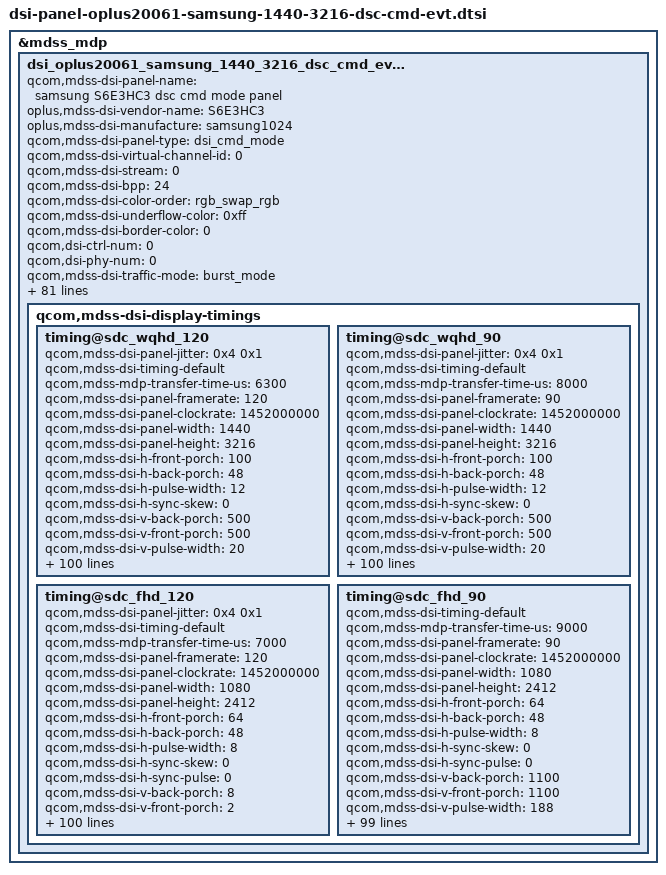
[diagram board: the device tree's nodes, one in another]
&mdss_mdp {
	dsi_oplus20061_samsung_1440_3216_dsc_cmd_evt: qcom,mdss_dsi_oplus20061_samsung_1440_3216_dsc_cmd_evt {
		qcom,mdss-dsi-panel-name = "samsung S6E3HC3 dsc cmd mode panel";
		oplus,mdss-dsi-vendor-name = "S6E3HC3";
		oplus,mdss-dsi-manufacture = "samsung1024";
		qcom,mdss-dsi-panel-type = "dsi_cmd_mode";
		qcom,mdss-dsi-virtual-channel-id = <0>;
		qcom,mdss-dsi-stream = <0>;
		qcom,mdss-dsi-bpp = <24>;
		qcom,mdss-dsi-color-order = "rgb_swap_rgb";
		qcom,mdss-dsi-underflow-color = <0xff>;
		qcom,mdss-dsi-border-color = <0>;
		qcom,dsi-ctrl-num = <0>;
		qcom,dsi-phy-num = <0>;
		qcom,mdss-dsi-traffic-mode = "burst_mode";
		qcom,mdss-dsi-lane-map = "lane_map_0123";
		qcom,mdss-dsi-bllp-eof-power-mode;
		qcom,mdss-dsi-bllp-power-mode;
		qcom,mdss-dsi-lane-0-state;
		qcom,mdss-dsi-lane-1-state;
		qcom,mdss-dsi-lane-2-state;
		qcom,mdss-dsi-lane-3-state;
		qcom,mdss-dsi-dma-trigger = "trigger_sw";
		qcom,mdss-loading-effect;
		qcom,mdss-dsi-mdp-trigger = "none";
		qcom,mdss-dsi-reset-sequence = <1 10>, <0 5>, <1 10>;
		qcom,mdss-dsi-te-pin-select = <1>;
		qcom,mdss-dsi-te-dcs-command = <1>;
		qcom,mdss-pan-physical-width-dimension = <71>;
		qcom,mdss-pan-physical-height-dimension = <157>;
		qcom,mdss-dsi-init-delay-us = <1000>;
		qcom,mdss-dsi-te-check-enable;
		qcom,mdss-dsi-te-using-te-pin;
		qcom,mdss-dsi-lp11-init;
		qcom,mdss-dsi-wr-mem-start = <0x2c>;
		qcom,mdss-dsi-wr-mem-continue = <0x3c>;
		/* HDR Setting */
		qcom,mdss-dsi-panel-hdr-enabled;
		qcom,mdss-dsi-panel-hdr-color-primaries = <15635 16450 34000 16000 13250 34500 7500 3000>;
		qcom,mdss-dsi-panel-peak-brightness = <5400000>;
		qcom,mdss-dsi-panel-average-brightness = <2000000>;
		qcom,mdss-dsi-panel-blackness-level = <4000>;

		qcom,esd-check-enabled;
		qcom,mdss-dsi-panel-status-check-mode = "reg_read";
		qcom,mdss-dsi-panel-status-command = [
						06 01 00 01 05 00 02 E9 00
						06 01 00 01 05 00 02 EE 00
						06 01 00 01 05 00 02 0A 00
						];
		qcom,mdss-dsi-panel-status-command-state = "dsi_hs_mode";
		qcom,mdss-dsi-panel-status-value = <0x00 0x00 0x00 0x00 0x00 0x9F>;
		qcom,mdss-dsi-panel-status-read-length = <4 1 1>;

		qcom,dynamic-mode-switch-enabled;
		qcom,dynamic-mode-switch-type = "dynamic-resolution-switch-immediate";
		qcom,mdss-dsi-display-timings {
			timing@sdc_wqhd_120{
				qcom,mdss-dsi-panel-jitter = <0x4 0x1>;
				qcom,mdss-dsi-timing-default;
				qcom,mdss-mdp-transfer-time-us = <6300>;
				qcom,mdss-dsi-panel-framerate = <120>;
				qcom,mdss-dsi-panel-clockrate = <1452000000>;
				qcom,mdss-dsi-panel-width = <1440>;
				qcom,mdss-dsi-panel-height = <3216>;

				qcom,mdss-dsi-h-front-porch = <100>;
				qcom,mdss-dsi-h-back-porch = <48>;
				qcom,mdss-dsi-h-pulse-width = <12>;
				qcom,mdss-dsi-h-sync-skew = <0>;
				qcom,mdss-dsi-v-back-porch = <500>;
				qcom,mdss-dsi-v-front-porch = <500>;
				qcom,mdss-dsi-v-pulse-width = <20>;
				qcom,mdss-dsi-h-sync-pulse = <0>;

				qcom,mdss-dsi-h-left-border = <0>;
				qcom,mdss-dsi-h-right-border = <0>;
				qcom,mdss-dsi-v-top-border = <0>;
				qcom,mdss-dsi-v-bottom-border = <0>;

				qcom,dsi-select-clocks = "mux_byte_clk0", "mux_pixel_clk0";

				oplus,fod-on-vblank = <2>;
				oplus,fod-off-vblank = <3>;
				qcom,mdss-dsi-panel-read-register-open-command = [
					39 01 00 00 00 00 03 F0 5A 5A
					];
				qcom,mdss-dsi-panel-id1-command = [
					06 01 00 00 00 00 01 E9
					];
				qcom,mdss-dsi-panel-read-register-close-command = [
					39 01 00 00 00 00 03 F0 A5 A5
					];
				qcom,mdss-dsi-timing-switch-command = [
					/* Resolution setting */
					/* CASET/PASET Setting */
					39 01 00 00 00 00 05 2A 00 00 05 9F
					39 01 00 00 00 00 05 2B 00 00 0C 8F
					/* Scaler Setting */
					39 01 00 00 00 00 03 F0 5A 5A
					15 01 00 00 00 00 02 C3 0C
					39 01 00 00 00 00 03 F0 A5 A5

					/* OPLUS ADFR OFF */
					39 00 00 00 00 00 03 F0 5A 5A				/* Level2 key Access Enable */
					39 00 00 00 00 00 03 FC 5A 5A				/* Level3 key Access Enable */
					39 00 00 00 00 00 02 B9 00					/* TP shift fixed*/
					39 00 00 00 00 00 04 B0 00 02 60
					15 00 00 00 00 00 02 60 00					/* OPLUS ADFR off */
					39 00 00 00 00 00 03 F2 00 01				/* 0x01, 0x00 : ADFR ON setting, 0x00, 0x01 : ADFR OFF Setting */
					15 00 00 00 00 00 02 F7 0F
					39 00 00 00 00 00 03 FC A5 A5				/* Level3 key Access Disable */
					39 01 00 00 00 00 03 F0 A5 A5				/* Level2 key Access Disable */

					/* SDC ADFR */
					39 00 00 00 00 00 03 F0 5A 5A				/* Level2 key Access Enable */
					39 00 00 00 00 00 04 B0 00 22 B9			/* TSP_HSYNC Fixed TE*/
					15 00 00 00 00 00 02 B9 21
					39 00 00 00 00 00 04 B0 00 3A B9
					39 00 00 00 00 00 02 B9 02					/* TSP_HSYNC Fixed TE 02:120  03:90 05:60 */
					39 00 00 00 00 00 04 B0 00 16 F2
					39 00 00 00 00 00 03 F2 1B 50				/* 0x1B, 0x50 : 120hz,  0x24, 0x70 : 90hz */
					39 00 00 00 00 00 03 BD 21 02				/* 0x21, 0x02 : 120hz,  0x21, 0x03 : 90hz */
					15 00 00 00 00 00 02 60 00					/* 0x00 : 120hz,  0x08 : 90hz */
					15 00 00 00 00 00 02 F7 0F
					39 01 00 00 11 00 03 F0 A5 A5				/* Level2 key Access Disable, wait 17ms for TE stable*/

					39 00 00 00 00 00 03 F0 5A 5A				/* Level2 key Access Enable */
					15 00 00 00 00 00 02 BD 23					/* 21 : Manual On  23 Auto On */
					39 00 00 00 00 00 04 B0 00 14 BD
					15 00 00 00 00 00 02 BD 0B					/* SDC auto mode min fps setting 0B: 10hz */
					15 00 00 00 00 00 02 F7 0F
					39 01 00 00 00 00 03 F0 A5 A5				/* Level2 key Access Disable */
				];
				qcom,mdss-dsi-on-command = [
					/* PPS setting */
					39 01 00 00 0B 00 5A 9E
					11 00 00 89 30 80 0C 90
					05 A0 00 43 02 D0 02 D0
					02 00 02 C2 00 20 06 89
					00 0A 00 0F 01 D2 01 24
					18 00 10 F0 03 0C 20 00
					06 0B 0B 33 0E 1C 2A 38
					46 54 62 69 70 77 79 7B
					7D 7E 01 02 01 00 09 40
					09 BE 19 FC 19 FA 19 F8
					1A 38 1A 78 1A B6 2A B6
					2A F4 2A F4 4B 34 63 74 00
					/* DSC enable */
					15 01 00 00 00 00 02 9D 01
					/*Sleep out */
					05 01 00 00 07 00 01 11

					/* TSP_VSYNC Fixed 120Hz Setting */
					39 01 00 00 00 00 03 F0 5A 5A
					39 01 00 00 00 00 04 B0 00 22 B9
					15 01 00 00 00 00 02 B9 21
					39 01 00 00 00 00 04 B0 00 3A B9
					15 01 00 00 00 00 02 B9 02
					15 01 00 00 00 00 02 F7 0F
					39 01 00 00 78 00 03 F0 A5 A5

					/* SDC ADFR 120hz */
					39 01 00 00 00 00 03 F0 5A 5A				/* Level2 key Access Enable */
					39 01 00 00 00 00 04 B0 00 16 F2
					39 01 00 00 00 00 03 F2 1B 50				/* 0x1B, 0x50 : 120hz,  0x24, 0x70 : 90hz */
					39 01 00 00 00 00 03 BD 21 02				/* 0x21, 0x02 : 120hz,  0x21, 0x03 : 90hz */
					15 01 00 00 00 00 02 60 00					/* 0x00 : 120hz,  0x08 : 90hz */
					15 01 00 00 00 00 02 F7 0F
					39 01 00 00 00 00 03 F0 A5 A5				/* Level2 key Access Disable */

					/* SDC auto mode */
					39 01 00 00 00 00 03 F0 5A 5A				/* Level2 key Access Enable */
					15 01 00 00 00 00 02 BD 23					/* 21 : Manual On  23 Auto On */
					39 00 00 00 00 00 04 B0 00 14 BD
					15 00 00 00 00 00 02 BD 0B					/* SDC auto mode min fps setting 0B: 10hz */
					15 01 00 00 00 00 02 F7 0F
					39 01 00 00 00 00 03 F0 A5 A5				/* Level2 key Access Disable */

					/* Common Setting */
					/* FQ_CON Setting */
					39 01 00 00 00 00 03 F0 5A 5A				/* Level2 key Access Enable */
					39 01 00 00 00 00 03 F2 00 01				/* FQ_CON Setting */
					39 01 00 00 00 00 03 F0 A5 A5				/* Level2 key Access Disable */
					/* TE(Vsync) ON/OFF */
					15 01 00 00 00 00 02 35 00					/* TE On(Vsync) */

					/* Resolution setting */
					/* CASET/PASET Setting */
					39 01 00 00 00 00 05 2A 00 00 05 9F
					39 01 00 00 00 00 05 2B 00 00 0C 8F
					/* Scaler Setting */
					39 01 00 00 00 00 03 F0 5A 5A
					15 01 00 00 00 00 02 C3 0C
					39 01 00 00 00 00 03 F0 A5 A5

					/* Loading effect compensation Control */
					39 01 00 00 00 00 03 F0 5A 5A				/* TEST KEY Enable */
					39 01 00 00 00 00 04 B0 02 B6 1D				/* Global Para */
					15 01 00 00 00 00 02 1D 25					/* Loading effect compensation Setting, 0x25: mode ON, 0x05:mode ON */
					39 01 00 00 00 00 03 F0 A5 A5

					/* Brightness Control */
					/* Dimming Setting */
					39 01 00 00 00 00 03 F0 5A 5A				/* Level2 key Access Enable */
					39 01 00 00 00 00 04 B0 00 0D 63
					15 01 00 00 00 00 02 63 01					/* Dimming Speed Setting */
					39 01 00 00 00 00 04 B0 00 0C 63
					15 01 00 00 00 00 02 63 20					/* ELVSS Dim Setting */
					39 01 00 00 00 00 03 F0 A5 A5				/* Level2 key Access Disable */
					15 01 00 00 00 00 02 53 28					/* WRCTRLD */
					39 01 00 00 00 00 03 51 07 FF				/* WRDISBV */
					15 01 00 00 00 00 02 F7 0F

					/** OPEC ON ***/
					39 01 00 00 00 00 03 F0 5A 5A
					39 01 00 00 00 00 04 B0 00 52 1F
					39 01 00 00 00 00 02 1F 02
					39 01 00 00 00 00 04 B0 00 54 1F
					39 01 00 00 00 00 02 1F 01
					39 01 00 00 00 00 03 F0 A5 A5

					/* ACL Mode */
					39 01 00 00 00 00 03 F0 5A 5A				/* Level2 key Access Enable */
					15 01 00 00 00 00 02 55 00					/* WRCABC, 0x00 : ACL Off */
					39 01 00 00 00 00 03 F0 A5 A5				/* Level2 key Access Disable */

					/* ELVSS DIM OFF  */
					39 01 00 00 00 00 03 F0 5A 5A
					39 01 00 00 00 00 04 B0 00 0C 63
					15 01 00 00 00 00 02 63 00
					39 01 00 00 00 00 03 F0 A5 A5

					//05 01 00 00 00 00 01 29
				];
				qcom,mdss-dsi-post-on-backlight = [
					/* Display On */
					05 01 00 00 00 00 01 29
				];
				qcom,mdss-dsi-off-command=[
					05 01 00 00 0A 00 02 28 00
					05 01 00 00 78 00 02 10 00
				];
				qcom,mdss-dsi-lp1-command = [
					//05 01 00 00 11 00 01 28
					/* AOD Mode ON Setting */
					39 01 00 00 00 00 03 F0 5A 5A
					15 01 00 00 00 00 02 53 24
					15 01 00 00 00 00 02 6A 00
					15 01 00 00 00 00 02 F7 0F
					15 01 00 00 00 00 02 49 01
					39 01 00 00 24 00 03 F0 A5 A5
					05 01 00 00 00 00 01 29
				];
				qcom,mdss-dsi-nolp-command = [
					/* AOD OFF */
					39 01 00 00 00 00 03 F0 5A 5A
					15 01 00 00 00 00 02 53 20
					15 01 00 00 00 00 02 F7 0F
					15 01 00 00 00 00 02 49 02
					39 01 00 00 00 00 03 F0 A5 A5
					/* ELVSS DIM OFF  */
					39 01 00 00 00 00 03 F0 5A 5A
					39 01 00 00 00 00 04 B0 00 0C 63
					15 01 00 00 00 00 02 63 00
					39 01 00 00 00 00 03 F0 A5 A5
					/* SDC ADFR */
					39 00 00 00 00 00 03 F0 5A 5A				/* Level2 key Access Enable */
					39 00 00 00 00 00 04 B0 00 22 B9			/* TSP_HSYNC Fixed TE*/
					15 00 00 00 00 00 02 B9 21
					39 00 00 00 00 00 04 B0 00 3A B9
					39 00 00 00 00 00 02 B9 02					/* TSP_HSYNC Fixed TE 02:120  03:90 05:60 */
					39 00 00 00 00 00 04 B0 00 16 F2
					39 00 00 00 00 00 03 F2 1B 50				/* 0x1B, 0x50 : 120hz,  0x24, 0x70 : 90hz */
					39 00 00 00 00 00 03 BD 21 02				/* 0x21, 0x02 : 120hz,  0x21, 0x03 : 90hz */
					15 00 00 00 00 00 02 60 00					/* 0x00 : 120hz,  0x08 : 90hz */
					15 00 00 00 00 00 02 F7 0F
					39 01 00 00 11 00 03 F0 A5 A5				/* Level2 key Access Disable, wait 17ms for TE stable*/

					/* Normal Mode */
					39 01 00 00 00 00 03 F0 5A 5A
					39 01 00 00 00 00 04 B0 00 01 49
					15 01 00 00 00 00 02 49 01
					15 01 00 00 00 00 02 53 20
					15 01 00 00 00 00 02 F7 0F
					39 01 00 00 00 00 03 F0 A5 A5
					/* AOR 16% */
					//39 01 00 00 00 00 03 F0 5A 5A
					//39 01 00 00 00 00 04 B0 00 01 BD
					//39 01 00 00 00 00 02 BD 02
					//39 01 00 00 00 00 04 B0 02 B9 65
					//39 01 00 00 00 00 07 65 01 5E 01 5E 01 5E
					//39 01 00 00 00 00 02 F7 0F
					//39 01 00 00 00 00 03 F0 A5 A5
				];
				qcom,mdss-dsi-aod-hbm-on-command = [
					/* Loading OFF */
					39 01 00 00 00 00 03 F0 5A 5A
					39 01 00 00 00 00 04 B0 02 B6 1D
					39 01 00 00 00 00 02 1D 05
					39 01 00 00 00 00 03 F0 A5 A5
					/* AOD OFF */
					39 01 00 00 00 00 03 F0 5A 5A
					39 01 00 00 00 00 02 53 20
					15 01 00 00 00 00 02 F7 0F
					15 01 00 00 00 00 02 49 02
					39 01 00 00 00 00 03 F0 A5 A5
					/* AOR 1.6% */
					39 01 00 00 00 00 03 F0 5A 5A
					39 01 00 00 00 00 04 B0 00 01 BD
					39 01 00 00 00 00 02 BD 00
					39 01 00 00 00 00 04 B0 02 B9 65
					39 01 00 00 00 00 07 65 00 AC 00 AC 00 AC
					39 01 00 00 00 00 02 F7 0F
					39 01 00 00 00 00 03 F0 A5 A5
					/* Hbm ON */
					39 01 00 00 00 00 03 F0 5A 5A
					39 01 00 00 00 00 04 B0 00 01 49
					39 01 00 00 00 00 02 49 00
					15 01 00 00 00 00 02 53 E0
					39 01 00 00 00 00 03 51 0B 7F
					15 01 00 00 00 00 02 F7 0F
					39 01 00 00 00 00 03 F0 A5 A5
				];
				qcom,mdss-dsi-aod-hbm-off-command = [
					/* HBM OFF */
					39 01 00 00 00 00 03 F0 5A 5A
					39 01 00 00 00 00 04 B0 00 01 49
					15 01 00 00 00 00 02 49 01
					15 01 00 00 00 00 02 53 20
					15 01 00 00 00 00 02 F7 0F
					39 01 00 00 00 00 03 F0 A5 A5
					/* AOD ON */
					39 01 00 00 00 00 03 F0 5A 5A
					15 01 00 00 00 00 02 53 24
					15 01 00 00 00 00 02 6A 00
					15 01 00 00 00 00 02 F7 0F
					39 01 00 00 00 00 02 49 01
					39 01 00 00 00 00 03 F0 A5 A5
				];
				qcom,mdss-dsi-hbm-off-command = [
					39 01 00 00 00 00 03 F0 5A 5A
					39 01 00 00 00 00 04 B0 00 01 49
					39 01 00 00 00 00 02 49 01
					15 01 00 00 00 00 02 53 20
					//39 01 00 00 05 00 03 51 05 14
					15 01 00 00 00 00 02 F7 0F
					39 01 00 00 00 00 03 F0 A5 A5
					/* Loading ON */
					//39 01 00 00 00 00 03 F0 5A 5A
					//39 01 00 00 00 00 04 B0 02 B6 1D
					//39 01 00 00 00 00 02 1D 25
					//39 01 00 00 00 00 03 F0 A5 A5
				];
				qcom,mdss-dsi-hbm-on-command = [
					/* Loading OFF */
					39 01 00 00 00 00 03 F0 5A 5A
					39 01 00 00 00 00 04 B0 02 B6 1D
					39 01 00 00 00 00 02 1D 05
					39 01 00 00 00 00 03 F0 A5 A5
					/* AOR 1.6% */
					39 01 00 00 00 00 03 F0 5A 5A
					39 01 00 00 00 00 04 B0 00 01 BD
					39 01 00 00 00 00 02 BD 00
					39 01 00 00 00 00 04 B0 02 B9 65
					39 01 00 00 00 00 07 65 00 AC 00 AC 00 AC
					39 01 00 00 00 00 02 F7 0F
					39 01 00 00 00 00 03 F0 A5 A5
					/* Hbm ON */
					39 01 00 00 00 00 03 F0 5A 5A
					39 01 00 00 00 00 04 B0 00 01 49
					39 01 00 00 00 00 02 49 00
					15 01 00 00 00 00 02 53 E0
					39 01 00 00 00 00 03 51 0B 7F
					15 01 00 00 00 00 02 F7 0F
					39 01 00 00 00 00 03 F0 A5 A5
				];
				qcom,mdss-dsi-normal-hbm-on-command = [
					/* Loading OFF */
					39 01 00 00 00 00 03 F0 5A 5A
					39 01 00 00 00 00 04 B0 02 B6 1D
					39 01 00 00 00 00 02 1D 05
					39 01 00 00 00 00 03 F0 A5 A5
					/* AOR 1.6% */
					39 01 00 00 00 00 03 F0 5A 5A
					39 01 00 00 00 00 04 B0 00 01 BD
					39 01 00 00 00 00 02 BD 00
					39 01 00 00 00 00 04 B0 02 B9 65
					39 01 00 00 00 00 07 65 00 AC 00 AC 00 AC
					39 01 00 00 00 00 02 F7 0F
					39 01 00 00 00 00 03 F0 A5 A5
					/* Hbm ON */
					39 01 00 00 00 00 03 F0 5A 5A
					39 01 00 00 00 00 04 B0 00 01 49
					39 01 00 00 00 00 02 49 00
					15 01 00 00 00 00 02 53 E0
					39 01 00 00 00 00 03 51 0B 7F
					15 01 00 00 00 00 02 F7 0F
					39 01 00 00 00 00 03 F0 A5 A5
				];
				qcom,mdss-dsi-aod-high-mode-command = [
					/* AOD 50nit */
					39 01 00 00 00 00 03 F0 5A 5A
					15 01 00 00 00 00 02 53 24
					39 01 00 00 00 00 02 6A 00
					39 01 00 00 00 00 03 F0 A5 A5
				];
				qcom,mdss-dsi-aod-low-mode-command = [
					/* AOD 10nit */
					39 01 00 00 00 00 03 F0 5A 5A
					15 01 00 00 00 00 02 53 27
					39 01 00 00 00 00 02 6A 00
					39 01 00 00 00 00 03 F0 A5 A5
				];
				qcom,mdss-dsi-seed-off-command = [
					/* SEED CRC OFF*/
					15 01 00 00 00 00 02 1C 00
					/* SEED CRC BYPASS */
					39 01 00 00 00 00 03 F0 5A 5A
					15 01 00 00 00 00 02 1D 01
					39 01 00 00 00 00 03 F0 A5 A5
				];
				qcom,mdss-dsi-seed-0-command = [
					/* SEED CRC Setting*/
					15 01 00 00 00 00 02 1C 05
					39 01 00 00 00 00 03 F0 5A 5A
					39 01 00 00 00 00 04 B0 00 01 1D
					/* SEED DCI-P3 Setting*/
					39 01 00 00 00 00 16 1D FF 00 00 00 FF 00 00 00 FF 00 FF FF FF 00 FF FF FF 00 FF FF FF
					15 01 00 00 00 00 02 1D 00
					39 01 00 00 00 00 03 F0 A5 A5
				];
				qcom,mdss-dsi-seed-1-command = [
					/* SEED CRC Setting*/
					15 01 00 00 00 00 02 1C 05
					39 01 00 00 00 00 03 F0 5A 5A
					39 01 00 00 00 00 04 B0 00 01 1D
					/* SEED DCI-P3 Setting*/
					39 01 00 00 00 00 16 1D FF 00 00 00 FF 00 00 00 FF 00 FF FF FF 00 FF FF FF 00 FF FF FF
					15 01 00 00 00 00 02 1D 00
					39 01 00 00 00 00 03 F0 A5 A5
				];
				qcom,mdss-dsi-seed-2-command = [
					/* SEED CRC Setting*/
					15 01 00 00 00 00 02 1C 05
					39 01 00 00 00 00 03 F0 5A 5A
					39 01 00 00 00 00 04 B0 00 01 1D
					/* SEED DCI-P3 Setting*/
					39 01 00 00 00 00 16 1D FF 00 00 00 FF 00 00 00 FF 00 FF FF FF 00 FF FF FF 00 FF FF FF
					15 01 00 00 00 00 02 1D 00
					39 01 00 00 00 00 03 F0 A5 A5
				];
				qcom,mdss-dsi-loading-effect-1-command = [
					39 01 00 00 00 00 03 F0 5A 5A
					39 01 00 00 00 00 04 B0 02 B6 1D
					39 01 00 00 00 00 02 1D 25
					39 01 00 00 00 00 04 B0 01 A5 1F
					39 01 00 00 00 00 09 1F E2 02 02 02 92 2C 6A 80
					39 01 00 00 00 00 04 B0 01 AD 1F
					39 01 00 00 00 00 07 1F 00 00 00 00 FF 90
					39 01 00 00 00 00 04 B0 01 B5 1F
					39 01 00 00 00 00 04 1F 49 00 10
					39 01 00 00 00 00 04 B0 01 BA 1F
					39 01 00 00 00 00 06 1F 05 FF 10 00 00
					39 01 00 00 00 00 04 B0 01 C1 1F
					39 01 00 00 00 00 03 1F 00 00
					39 01 00 00 00 00 04 B0 01 C5 1F
					39 01 00 00 00 00 05 1F 03 FF 21 3C
					39 01 00 00 00 00 03 F0 A5 A5
				];
				qcom,mdss-dsi-loading-effect-2-command = [
					39 01 00 00 00 00 03 F0 5A 5A
					39 01 00 00 00 00 04 B0 02 B6 1D
					39 01 00 00 00 00 02 1D 25
					39 01 00 00 00 00 04 B0 01 A5 1F
					39 01 00 00 00 00 09 1F E2 02 02 02 92 2C 6A 80
					39 01 00 00 00 00 04 B0 01 AD 1F
					39 01 00 00 00 00 07 1F 81 67 8F 72 FF 90
					39 01 00 00 00 00 04 B0 01 B5 1F
					39 01 00 00 00 00 04 1F 49 00 10
					39 01 00 00 00 00 04 B0 01 BA 1F
					39 01 00 00 00 00 06 1F 05 FF 10 00 00
					39 01 00 00 00 00 04 B0 01 C1 1F
					39 01 00 00 00 00 03 1F 00 00
					39 01 00 00 00 00 04 B0 01 C5 1F
					39 01 00 00 00 00 05 1F 03 FF 21 3C
					39 01 00 00 00 00 03 F0 A5 A5
				];
				qcom,mdss-dsi-loading-effect-off-command = [
					39 01 00 00 00 00 03 F0 5A 5A
					39 01 00 00 00 00 04 B0 02 B6 1D
					39 01 00 00 00 00 02 1D 05
					39 01 00 00 00 00 04 B0 01 A5 1F
					39 01 00 00 00 00 09 1F E2 02 02 02 92 2C 6A 80
					39 01 00 00 00 00 04 B0 01 AD 1F
					39 01 00 00 00 00 07 1F 71 27 4E 0B FF 9F
					39 01 00 00 00 00 04 B0 01 B5 1F
					39 01 00 00 00 00 04 1F 49 00 10
					39 01 00 00 00 00 04 B0 01 BA 1F
					39 01 00 00 00 00 06 1F 05 FF 10 00 00
					39 01 00 00 00 00 04 B0 01 C1 1F
					39 01 00 00 00 00 03 1F 00 00
					39 01 00 00 00 00 04 B0 01 C5 1F
					39 01 00 00 00 00 05 1F 03 FF 21 3C
					39 01 00 00 00 00 03 F0 A5 A5
				];
				qcom,mdss-dsi-aod-hbm-on-command-state = "dsi_hs_mode";
				qcom,mdss-dsi-aod-hbm-off-command-state = "dsi_hs_mode";
				qcom,mdss-dsi-timing-switch-command-state = "dsi_hs_mode";
				qcom,mdss-dsi-on-command-state = "dsi_lp_mode";
				qcom,mdss-dsi-off-command-state = "dsi_hs_mode";
				qcom,mdss-dsi-seed-off-command-state = "dsi_hs_mode";
				qcom,mdss-dsi-seed-0-command-state = "dsi_hs_mode";
				qcom,mdss-dsi-seed-1-command-state = "dsi_hs_mode";
				qcom,mdss-dsi-seed-2-command-state = "dsi_hs_mode";
				qcom,mdss-dsi-loading-effect-1-command-state = "dsi_hs_mode";
				qcom,mdss-dsi-loading-effect-2-command-state = "dsi_hs_mode";
				qcom,mdss-dsi-loading-effect-off-command-state = "dsi_hs_mode";
				qcom,mdss-dsi-hbm-on-command-state = "dsi_hs_mode";
				qcom,mdss-dsi-hbm-off-command-state = "dsi_hs_mode";

				qcom,compression-mode = "dsc";
				qcom,lm-split = <720 720>;
				qcom,mdss-dsc-encoders = <2>;
				qcom,mdss-dsc-slice-height = <67>;
				qcom,mdss-dsc-slice-width = <720>;
				qcom,mdss-dsc-slice-per-pkt = <2>;
				qcom,mdss-dsc-bit-per-component = <8>;
				qcom,mdss-dsc-bit-per-pixel = <8>;
				qcom,mdss-dsc-block-prediction-enable;
				qcom,mdss-dsi-panel-id1-command-state = "dsi_lp_mode";
				qcom,mdss-dsi-panel-read-register-open-state = "dsi_lp_mode";
				qcom,mdss-dsi-panel-read-register-close-state = "dsi_lp_mode";
			};
			timing@sdc_wqhd_90{
				qcom,mdss-dsi-panel-jitter = <0x4 0x1>;
				qcom,mdss-dsi-timing-default;
				qcom,mdss-mdp-transfer-time-us = <8000>;
				qcom,mdss-dsi-panel-framerate = <90>;
				qcom,mdss-dsi-panel-clockrate = <1452000000>;
				qcom,mdss-dsi-panel-width = <1440>;
				qcom,mdss-dsi-panel-height = <3216>;

				qcom,mdss-dsi-h-front-porch = <100>;
				qcom,mdss-dsi-h-back-porch = <48>;
				qcom,mdss-dsi-h-pulse-width = <12>;
				qcom,mdss-dsi-h-sync-skew = <0>;
				qcom,mdss-dsi-v-back-porch = <500>;
				qcom,mdss-dsi-v-front-porch = <500>;
				qcom,mdss-dsi-v-pulse-width = <20>;
				qcom,mdss-dsi-h-sync-pulse = <0>;

				qcom,mdss-dsi-h-left-border = <0>;
				qcom,mdss-dsi-h-right-border = <0>;
				qcom,mdss-dsi-v-top-border = <0>;
				qcom,mdss-dsi-v-bottom-border = <0>;

				qcom,dsi-select-clocks = "mux_byte_clk0", "mux_pixel_clk0";

				oplus,fod-on-vblank = <2>;
				oplus,fod-off-vblank = <3>;
				qcom,mdss-dsi-panel-read-register-open-command = [
					39 01 00 00 00 00 03 F0 5A 5A
					];
				qcom,mdss-dsi-panel-id1-command = [
					06 01 00 00 00 00 01 E9
					];
				qcom,mdss-dsi-panel-read-register-close-command = [
					39 01 00 00 00 00 03 F0 A5 A5
					];
				qcom,mdss-dsi-timing-switch-command = [
					/* Resolution setting */
					/* CASET/PASET Setting */
					39 01 00 00 00 00 05 2A 00 00 05 9F
					39 01 00 00 00 00 05 2B 00 00 0C 8F
					/* Scaler Setting */
					39 01 00 00 00 00 03 F0 5A 5A
					15 01 00 00 00 00 02 C3 0C
					39 01 00 00 00 00 03 F0 A5 A5

					/* OPLUS ADFR OFF */
					39 00 00 00 00 00 03 F0 5A 5A				/* Level2 key Access Enable */
					39 00 00 00 00 00 03 FC 5A 5A				/* Level3 key Access Enable */
					39 00 00 00 00 00 02 B9 00					/* TP shift fixed*/
					39 00 00 00 00 00 04 B0 00 02 60
					15 00 00 00 00 00 02 60 00					/* OPLUS ADFR off */
					39 00 00 00 00 00 03 F2 00 01				/* 0x01, 0x00 : ADFR ON setting, 0x00, 0x01 : ADFR OFF Setting */
					15 00 00 00 00 00 02 F7 0F
					39 00 00 00 00 00 03 FC A5 A5				/* Level3 key Access Disable */
					39 01 00 00 00 00 03 F0 A5 A5				/* Level2 key Access Disable */

					/* SDC ADFR */
					39 00 00 00 00 00 03 F0 5A 5A				/* Level2 key Access Enable */
					39 00 00 00 00 00 04 B0 00 22 B9			/* TSP_HSYNC Fixed TE*/
					15 00 00 00 00 00 02 B9 21
					39 00 00 00 00 00 04 B0 00 3A B9
					39 00 00 00 00 00 02 B9 03					/* TSP_HSYNC Fixed TE 02:120  03:90 05:60 */
					39 00 00 00 00 00 04 B0 00 16 F2
					39 00 00 00 00 00 03 F2 24 70				/* 0x1B, 0x50 : 120hz,  0x24, 0x70 : 90hz */
					39 00 00 00 00 00 03 BD 21 03				/* 0x21, 0x02 : 120hz,  0x21, 0x03 : 90hz */
					15 00 00 00 00 00 02 60 08					/* 0x00 : 120hz,  0x08 : 90hz */
					15 00 00 00 00 00 02 F7 0F
					39 01 00 00 11 00 03 F0 A5 A5				/* Level2 key Access Disable, wait 17ms for TE stable*/

					39 00 00 00 00 00 03 F0 5A 5A				/* Level2 key Access Enable */
					15 00 00 00 00 00 02 BD 23					/* 21 : Manual On  23 Auto On */
					39 00 00 00 00 00 04 B0 00 14 BD
					15 00 00 00 00 00 02 BD 05					/* SDC auto mode min fps setting 05: 15hz */
					15 00 00 00 00 00 02 F7 0F
					39 01 00 00 00 00 03 F0 A5 A5				/* Level2 key Access Disable */
				];
				qcom,mdss-dsi-on-command = [
					/* PPS setting */
					39 01 00 00 0B 00 5A 9E
					11 00 00 89 30 80 0C 90
					05 A0 00 43 02 D0 02 D0
					02 00 02 C2 00 20 06 89
					00 0A 00 0F 01 D2 01 24
					18 00 10 F0 03 0C 20 00
					06 0B 0B 33 0E 1C 2A 38
					46 54 62 69 70 77 79 7B
					7D 7E 01 02 01 00 09 40
					09 BE 19 FC 19 FA 19 F8
					1A 38 1A 78 1A B6 2A B6
					2A F4 2A F4 4B 34 63 74 00
					/* DSC enable */
					15 01 00 00 00 00 02 9D 01
					/*Sleep out */
					05 01 00 00 07 00 01 11

					/* TSP_VSYNC Fixed 90hz Setting */
					39 00 00 00 00 00 03 F0 5A 5A
					39 00 00 00 00 00 04 B0 00 22 B9
					15 00 00 00 00 00 02 B9 21
					39 00 00 00 00 00 04 B0 00 3A B9
					15 00 00 00 00 00 02 B9 03					/* 02 : Fixed 120Hz TE 03 : Fixed 90Hz TE 05 : Fixed 60Hz TE*/
					15 00 00 00 00 00 02 F7 0F
					39 01 00 00 78 00 03 F0 A5 A5

					/* SDC ADFR 120hz <-> 90hz Transition */
					39 00 00 00 00 00 03 F0 5A 5A				/* Level2 key Access Enable */
					39 00 00 00 00 00 04 B0 00 16 F2
					39 00 00 00 00 00 03 F2 24 70				/* 0x1B, 0x50 : 120hz,  0x24, 0x70 : 90hz */
					39 00 00 00 00 00 03 BD 21 03				/* 0x21, 0x02 : 120hz,  0x21, 0x03 : 90hz */
					15 00 00 00 00 00 02 60 08					/* 0x00 : 120hz,  0x08 : 90hz */
					15 00 00 00 00 00 02 F7 0F
					39 01 00 00 00 00 03 F0 A5 A5				/* Level2 key Access Disable */

					/* SDC auto mode */
					39 00 00 00 00 00 03 F0 5A 5A				/* Level2 key Access Enable */
					15 00 00 00 00 00 02 BD 23					/* 21 : Manual On  23 Auto On */
					39 00 00 00 00 00 04 B0 00 14 BD
					15 00 00 00 00 00 02 BD 05					/* SDC auto mode min fps setting 05: 15hz */
					15 00 00 00 00 00 02 F7 0F
					39 01 00 00 00 00 03 F0 A5 A5				/* Level2 key Access Disable */

					/* Common Setting */
					/* FQ_CON Setting */
					39 01 00 00 00 00 03 F0 5A 5A				/* Level2 key Access Enable */
					39 01 00 00 00 00 03 F2 00 01				/* FQ_CON Setting */
					39 01 00 00 00 00 03 F0 A5 A5				/* Level2 key Access Disable */
					/* TE(Vsync) ON/OFF */
					15 01 00 00 00 00 02 35 00					/* TE On(Vsync)  00:on 01:off*/

					/* Resolution setting */
					/* CASET/PASET Setting */
					39 01 00 00 00 00 05 2A 00 00 05 9F
					39 01 00 00 00 00 05 2B 00 00 0C 8F
					/* Scaler Setting */
					39 01 00 00 00 00 03 F0 5A 5A
					15 01 00 00 00 00 02 C3 0C
					39 01 00 00 00 00 03 F0 A5 A5

					/* Loading effect compensation Control */
					39 01 00 00 00 00 03 F0 5A 5A				/* TEST KEY Enable */
					39 01 00 00 00 00 04 B0 02 B6 1D			/* Global Para */
					15 01 00 00 00 00 02 1D 25					/* Loading effect compensation Setting, 0x25: mode ON, 0x05:   mode ON */
					39 01 00 00 00 00 03 F0 A5 A5

					/* Brightness Control */
					/* Dimming Setting */
					39 01 00 00 00 00 03 F0 5A 5A				/* Level2 key Access Enable */
					39 01 00 00 00 00 04 B0 00 0D 63
					15 01 00 00 00 00 02 63 01					/* Dimming Speed Setting */
					39 01 00 00 00 00 04 B0 00 0C 63
					15 01 00 00 00 00 02 63 20					/* ELVSS Dim Setting */
					39 01 00 00 00 00 03 F0 A5 A5				/* Level2 key Access Disable */
					15 01 00 00 00 00 02 53 28					/* WRCTRLD */
					39 01 00 00 00 00 03 51 07 FF				/* WRDISBV */
					15 01 00 00 00 00 02 F7 0F

					/** OPEC ON ***/
					39 01 00 00 00 00 03 F0 5A 5A
					39 01 00 00 00 00 04 B0 00 52 1F
					39 01 00 00 00 00 02 1F 02
					39 01 00 00 00 00 04 B0 00 54 1F
					39 01 00 00 00 00 02 1F 01
					39 01 00 00 00 00 03 F0 A5 A5

					/* ACL Mode */
					39 01 00 00 00 00 03 F0 5A 5A				/* Level2 key Access Enable */
					15 01 00 00 00 00 02 55 00					/* WRCABC, 0x00 : ACL Off */
					39 01 00 00 00 00 03 F0 A5 A5				/* Level2 key Access Disable */
					/* ELVSS DIM OFF  */
					39 01 00 00 00 00 03 F0 5A 5A
					39 01 00 00 00 00 04 B0 00 0C 63
					15 01 00 00 00 00 02 63 00
					39 01 00 00 00 00 03 F0 A5 A5
					//05 01 00 00 00 00 01 29
				];
				qcom,mdss-dsi-post-on-backlight = [
					/* Display On */
					05 01 00 00 00 00 01 29
				];
				qcom,mdss-dsi-off-command=[
					05 01 00 00 0A 00 02 28 00
					05 01 00 00 78 00 02 10 00
				];
				qcom,mdss-dsi-lp1-command = [
					//05 01 00 00 11 00 01 28
					/* AOD Mode ON Setting */
					39 01 00 00 00 00 03 F0 5A 5A
					15 01 00 00 00 00 02 53 24
					15 01 00 00 00 00 02 6A 00
					15 01 00 00 00 00 02 F7 0F
					15 01 00 00 00 00 02 49 01
					39 01 00 00 24 00 03 F0 A5 A5
					05 01 00 00 00 00 01 29
				];
				qcom,mdss-dsi-nolp-command = [
					/* AOD OFF */
					39 01 00 00 00 00 03 F0 5A 5A
					15 01 00 00 00 00 02 53 20
					15 01 00 00 00 00 02 F7 0F
					15 01 00 00 00 00 02 49 02
					39 01 00 00 00 00 03 F0 A5 A5
					/* SDC ADFR */
					39 00 00 00 00 00 03 F0 5A 5A				/* Level2 key Access Enable */
					39 00 00 00 00 00 04 B0 00 22 B9			/* TSP_HSYNC Fixed TE*/
					15 00 00 00 00 00 02 B9 21
					39 00 00 00 00 00 04 B0 00 3A B9
					39 00 00 00 00 00 02 B9 03					/* TSP_HSYNC Fixed TE 02:120  03:90 05:60 */
					39 00 00 00 00 00 04 B0 00 16 F2
					39 00 00 00 00 00 03 F2 24 70				/* 0x1B, 0x50 : 120hz,  0x24, 0x70 : 90hz */
					39 00 00 00 00 00 03 BD 21 03				/* 0x21, 0x02 : 120hz,  0x21, 0x03 : 90hz */
					15 00 00 00 00 00 02 60 08					/* 0x00 : 120hz,  0x08 : 90hz */
					15 00 00 00 00 00 02 F7 0F
					39 01 00 00 11 00 03 F0 A5 A5				/* Level2 key Access Disable, wait 17ms for TE stable*/
					/* ELVSS DIM OFF  */
					39 01 00 00 00 00 03 F0 5A 5A
					39 01 00 00 00 00 04 B0 00 0C 63
					15 01 00 00 00 00 02 63 00
					39 01 00 00 00 00 03 F0 A5 A5
					/* Normal Mode */
					39 01 00 00 00 00 03 F0 5A 5A
					39 01 00 00 00 00 04 B0 00 01 49
					15 01 00 00 00 00 02 49 01
					15 01 00 00 00 00 02 53 20
					15 01 00 00 00 00 02 F7 0F
					39 01 00 00 00 00 03 F0 A5 A5
					/* AOR 16% */
					//39 01 00 00 00 00 03 F0 5A 5A
					//39 01 00 00 00 00 04 B0 00 01 BD
					//39 01 00 00 00 00 02 BD 02
					//39 01 00 00 00 00 04 B0 02 B9 65
					//39 01 00 00 00 00 07 65 01 5E 01 5E 01 5E
					//39 01 00 00 00 00 02 F7 0F
					//39 01 00 00 00 00 03 F0 A5 A5
				];
				qcom,mdss-dsi-aod-hbm-on-command = [
					/* Loading OFF */
					39 01 00 00 00 00 03 F0 5A 5A
					39 01 00 00 00 00 04 B0 02 B6 1D
					39 01 00 00 00 00 02 1D 05
					39 01 00 00 00 00 03 F0 A5 A5
					/* AOD OFF */
					39 01 00 00 00 00 03 F0 5A 5A
					39 01 00 00 00 00 02 53 20
					15 01 00 00 00 00 02 F7 0F
					15 01 00 00 00 00 02 49 02
					39 01 00 00 00 00 03 F0 A5 A5
					/* AOR 1.6% */
					39 01 00 00 00 00 03 F0 5A 5A
					39 01 00 00 00 00 04 B0 00 01 BD
					39 01 00 00 00 00 02 BD 00
					39 01 00 00 00 00 04 B0 02 B9 65
					39 01 00 00 00 00 07 65 00 AC 00 AC 00 AC
					39 01 00 00 00 00 02 F7 0F
					39 01 00 00 00 00 03 F0 A5 A5
					/* Hbm ON */
					39 01 00 00 00 00 03 F0 5A 5A
					39 01 00 00 00 00 04 B0 00 01 49
					39 01 00 00 00 00 02 49 00
					15 01 00 00 00 00 02 53 E0
					39 01 00 00 00 00 03 51 0B 7F
					15 01 00 00 00 00 02 F7 0F
					39 01 00 00 00 00 03 F0 A5 A5
				];
				qcom,mdss-dsi-aod-hbm-off-command = [
					/* HBM OFF */
					39 01 00 00 00 00 03 F0 5A 5A
					39 01 00 00 00 00 04 B0 00 01 49
					15 01 00 00 00 00 02 49 01
					15 01 00 00 00 00 02 53 20
					15 01 00 00 00 00 02 F7 0F
					39 01 00 00 00 00 03 F0 A5 A5
					/* AOD ON */
					39 01 00 00 00 00 03 F0 5A 5A
					15 01 00 00 00 00 02 53 24
					15 01 00 00 00 00 02 6A 00
					15 01 00 00 00 00 02 F7 0F
					39 01 00 00 00 00 02 49 01
					39 01 00 00 00 00 03 F0 A5 A5
				];
				qcom,mdss-dsi-hbm-off-command = [
					39 01 00 00 00 00 03 F0 5A 5A
					39 01 00 00 00 00 04 B0 00 01 49
					39 01 00 00 00 00 02 49 01
					15 01 00 00 00 00 02 53 20
					//39 01 00 00 05 00 03 51 05 14
					15 01 00 00 00 00 02 F7 0F
					39 01 00 00 00 00 03 F0 A5 A5
					/* Loading ON */
					//39 01 00 00 00 00 03 F0 5A 5A
					//39 01 00 00 00 00 04 B0 02 B6 1D
					//39 01 00 00 00 00 02 1D 25
					//39 01 00 00 00 00 03 F0 A5 A5
				];
				qcom,mdss-dsi-hbm-on-command = [
					/* Loading OFF */
					39 01 00 00 00 00 03 F0 5A 5A
					39 01 00 00 00 00 04 B0 02 B6 1D
					39 01 00 00 00 00 02 1D 05
					39 01 00 00 00 00 03 F0 A5 A5
					/* AOR 1.6% */
					39 01 00 00 00 00 03 F0 5A 5A
					39 01 00 00 00 00 04 B0 00 01 BD
					39 01 00 00 00 00 02 BD 00
					39 01 00 00 00 00 04 B0 02 B9 65
					39 01 00 00 00 00 07 65 00 AC 00 AC 00 AC
					39 01 00 00 00 00 02 F7 0F
					39 01 00 00 00 00 03 F0 A5 A5
					/* Hbm ON */
					39 01 00 00 00 00 03 F0 5A 5A
					39 01 00 00 00 00 04 B0 00 01 49
					39 01 00 00 00 00 02 49 00
					15 01 00 00 00 00 02 53 E0
					39 01 00 00 00 00 03 51 0B 7F
					15 01 00 00 00 00 02 F7 0F
					39 01 00 00 00 00 03 F0 A5 A5
				];
				qcom,mdss-dsi-normal-hbm-on-command = [
					/* Loading OFF */
					39 01 00 00 00 00 03 F0 5A 5A
					39 01 00 00 00 00 04 B0 02 B6 1D
					39 01 00 00 00 00 02 1D 05
					39 01 00 00 00 00 03 F0 A5 A5
					/* AOR 1.6% */
					39 01 00 00 00 00 03 F0 5A 5A
					39 01 00 00 00 00 04 B0 00 01 BD
					39 01 00 00 00 00 02 BD 00
					39 01 00 00 00 00 04 B0 02 B9 65
					39 01 00 00 00 00 07 65 00 AC 00 AC 00 AC
					39 01 00 00 00 00 02 F7 0F
					39 01 00 00 00 00 03 F0 A5 A5
					/* Hbm ON */
					39 01 00 00 00 00 03 F0 5A 5A
					39 01 00 00 00 00 04 B0 00 01 49
					39 01 00 00 00 00 02 49 00
					15 01 00 00 00 00 02 53 E0
					39 01 00 00 00 00 03 51 0B 7F
					15 01 00 00 00 00 02 F7 0F
					39 01 00 00 00 00 03 F0 A5 A5
				];
				qcom,mdss-dsi-aod-high-mode-command = [
					/* AOD 50nit */
					39 01 00 00 00 00 03 F0 5A 5A
					15 01 00 00 00 00 02 53 24
					39 01 00 00 00 00 02 6A 00
					39 01 00 00 00 00 03 F0 A5 A5
				];
				qcom,mdss-dsi-aod-low-mode-command = [
					/* AOD 10nit */
					39 01 00 00 00 00 03 F0 5A 5A
					15 01 00 00 00 00 02 53 27
					39 01 00 00 00 00 02 6A 00
					39 01 00 00 00 00 03 F0 A5 A5
				];
				qcom,mdss-dsi-seed-off-command = [
					/* SEED CRC OFF*/
					15 01 00 00 00 00 02 1C 00
					/* SEED CRC BYPASS */
					39 01 00 00 00 00 03 F0 5A 5A
					15 01 00 00 00 00 02 1D 01
					39 01 00 00 00 00 03 F0 A5 A5
				];
				qcom,mdss-dsi-seed-0-command = [
					/* SEED CRC Setting*/
					15 01 00 00 00 00 02 1C 05
					39 01 00 00 00 00 03 F0 5A 5A
					39 01 00 00 00 00 04 B0 00 01 1D
					/* SEED DCI-P3 Setting*/
					39 01 00 00 00 00 16 1D FF 00 00 00 FF 00 00 00 FF 00 FF FF FF 00 FF FF FF 00 FF FF FF
					15 01 00 00 00 00 02 1D 00
					39 01 00 00 00 00 03 F0 A5 A5
				];
				qcom,mdss-dsi-seed-1-command = [
					/* SEED CRC Setting*/
					15 01 00 00 00 00 02 1C 05
					39 01 00 00 00 00 03 F0 5A 5A
					39 01 00 00 00 00 04 B0 00 01 1D
					/* SEED DCI-P3 Setting*/
					39 01 00 00 00 00 16 1D FF 00 00 00 FF 00 00 00 FF 00 FF FF FF 00 FF FF FF 00 FF FF FF
					15 01 00 00 00 00 02 1D 00
					39 01 00 00 00 00 03 F0 A5 A5
				];
				qcom,mdss-dsi-seed-2-command = [
					/* SEED CRC Setting*/
					15 01 00 00 00 00 02 1C 05
					39 01 00 00 00 00 03 F0 5A 5A
					39 01 00 00 00 00 04 B0 00 01 1D
					/* SEED DCI-P3 Setting*/
					39 01 00 00 00 00 16 1D FF 00 00 00 FF 00 00 00 FF 00 FF FF FF 00 FF FF FF 00 FF FF FF
					15 01 00 00 00 00 02 1D 00
					39 01 00 00 00 00 03 F0 A5 A5
				];
				qcom,mdss-dsi-loading-effect-1-command = [
					39 01 00 00 00 00 03 F0 5A 5A
					39 01 00 00 00 00 04 B0 02 B6 1D
					39 01 00 00 00 00 02 1D 25
					39 01 00 00 00 00 04 B0 01 A5 1F
					39 01 00 00 00 00 09 1F E2 02 02 02 92 2C 6A 80
					39 01 00 00 00 00 04 B0 01 AD 1F
					39 01 00 00 00 00 07 1F 00 00 00 00 FF 90
					39 01 00 00 00 00 04 B0 01 B5 1F
					39 01 00 00 00 00 04 1F 49 00 10
					39 01 00 00 00 00 04 B0 01 BA 1F
					39 01 00 00 00 00 06 1F 05 FF 10 00 00
					39 01 00 00 00 00 04 B0 01 C1 1F
					39 01 00 00 00 00 03 1F 00 00
					39 01 00 00 00 00 04 B0 01 C5 1F
					39 01 00 00 00 00 05 1F 03 FF 21 3C
					39 01 00 00 00 00 03 F0 A5 A5
				];
				qcom,mdss-dsi-loading-effect-2-command = [
					39 01 00 00 00 00 03 F0 5A 5A
					39 01 00 00 00 00 04 B0 02 B6 1D
					39 01 00 00 00 00 02 1D 25
					39 01 00 00 00 00 04 B0 01 A5 1F
					39 01 00 00 00 00 09 1F E2 02 02 02 92 2C 6A 80
					39 01 00 00 00 00 04 B0 01 AD 1F
					39 01 00 00 00 00 07 1F 81 67 8F 72 FF 90
					39 01 00 00 00 00 04 B0 01 B5 1F
					39 01 00 00 00 00 04 1F 49 00 10
					39 01 00 00 00 00 04 B0 01 BA 1F
					39 01 00 00 00 00 06 1F 05 FF 10 00 00
					39 01 00 00 00 00 04 B0 01 C1 1F
					39 01 00 00 00 00 03 1F 00 00
					39 01 00 00 00 00 04 B0 01 C5 1F
					39 01 00 00 00 00 05 1F 03 FF 21 3C
					39 01 00 00 00 00 03 F0 A5 A5
				];
				qcom,mdss-dsi-loading-effect-off-command = [
					39 01 00 00 00 00 03 F0 5A 5A
					39 01 00 00 00 00 04 B0 02 B6 1D
					39 01 00 00 00 00 02 1D 05
					39 01 00 00 00 00 04 B0 01 A5 1F
					39 01 00 00 00 00 09 1F E2 02 02 02 92 2C 6A 80
					39 01 00 00 00 00 04 B0 01 AD 1F
					39 01 00 00 00 00 07 1F 71 27 4E 0B FF 9F
					39 01 00 00 00 00 04 B0 01 B5 1F
					39 01 00 00 00 00 04 1F 49 00 10
					39 01 00 00 00 00 04 B0 01 BA 1F
					39 01 00 00 00 00 06 1F 05 FF 10 00 00
					39 01 00 00 00 00 04 B0 01 C1 1F
					39 01 00 00 00 00 03 1F 00 00
					39 01 00 00 00 00 04 B0 01 C5 1F
					39 01 00 00 00 00 05 1F 03 FF 21 3C
					39 01 00 00 00 00 03 F0 A5 A5
				];
				qcom,mdss-dsi-aod-hbm-on-command-state = "dsi_hs_mode";
				qcom,mdss-dsi-aod-hbm-off-command-state = "dsi_hs_mode";
				qcom,mdss-dsi-timing-switch-command-state = "dsi_hs_mode";
				qcom,mdss-dsi-on-command-state = "dsi_lp_mode";
				qcom,mdss-dsi-off-command-state = "dsi_hs_mode";
				qcom,mdss-dsi-seed-off-command-state = "dsi_hs_mode";
				qcom,mdss-dsi-seed-0-command-state = "dsi_hs_mode";
				qcom,mdss-dsi-seed-1-command-state = "dsi_hs_mode";
				qcom,mdss-dsi-seed-2-command-state = "dsi_hs_mode";
				qcom,mdss-dsi-loading-effect-1-command-state = "dsi_hs_mode";
				qcom,mdss-dsi-loading-effect-2-command-state = "dsi_hs_mode";
				qcom,mdss-dsi-loading-effect-off-command-state = "dsi_hs_mode";
				qcom,mdss-dsi-hbm-on-command-state = "dsi_hs_mode";
				qcom,mdss-dsi-hbm-off-command-state = "dsi_hs_mode";

				qcom,compression-mode = "dsc";
				qcom,lm-split = <720 720>;
				qcom,mdss-dsc-encoders = <2>;
				qcom,mdss-dsc-slice-height = <67>;
				qcom,mdss-dsc-slice-width = <720>;
				qcom,mdss-dsc-slice-per-pkt = <2>;
				qcom,mdss-dsc-bit-per-component = <8>;
				qcom,mdss-dsc-bit-per-pixel = <8>;
				qcom,mdss-dsc-block-prediction-enable;
				qcom,mdss-dsi-panel-id1-command-state = "dsi_lp_mode";
				qcom,mdss-dsi-panel-read-register-open-state = "dsi_lp_mode";
				qcom,mdss-dsi-panel-read-register-close-state = "dsi_lp_mode";
			};
			timing@sdc_fhd_120{
				qcom,mdss-dsi-panel-jitter = <0x4 0x1>;
				qcom,mdss-dsi-timing-default;
				qcom,mdss-mdp-transfer-time-us = <7000>;
				qcom,mdss-dsi-panel-framerate = <120>;
				qcom,mdss-dsi-panel-clockrate = <1452000000>;
				qcom,mdss-dsi-panel-width = <1080>;
				qcom,mdss-dsi-panel-height = <2412>;

				qcom,mdss-dsi-h-front-porch = <64>;
				qcom,mdss-dsi-h-back-porch = <48>;
				qcom,mdss-dsi-h-pulse-width = <8>;
				qcom,mdss-dsi-h-sync-skew = <0>;
				qcom,mdss-dsi-h-sync-pulse = <0>;
				qcom,mdss-dsi-v-back-porch = <8>;
				qcom,mdss-dsi-v-front-porch = <2>;
				qcom,mdss-dsi-v-pulse-width = <2>;
				qcom,mdss-dsi-h-left-border = <0>;
				qcom,mdss-dsi-h-right-border = <0>;
				qcom,mdss-dsi-v-top-border = <0>;
				qcom,mdss-dsi-v-bottom-border = <0>;

				qcom,dsi-select-clocks = "mux_byte_clk0", "mux_pixel_clk0";

				oplus,fod-on-vblank = <2>;
				oplus,fod-off-vblank = <3>;
				qcom,mdss-dsi-panel-read-register-open-command = [
					39 01 00 00 00 00 03 F0 5A 5A
					];
				qcom,mdss-dsi-panel-id1-command = [
					06 01 00 00 00 00 01 E9
					];
				qcom,mdss-dsi-panel-read-register-close-command = [
					39 01 00 00 00 00 03 F0 A5 A5
					];
				qcom,mdss-dsi-timing-switch-command = [
					/* Resolution setting */
					/* CASET/PASET Setting */
					39 01 00 00 00 00 05 2A 00 00 04 37
					39 01 00 00 00 00 05 2B 00 00 09 6B
					/* Scaler Setting */
					39 01 00 00 00 00 03 F0 5A 5A
					15 01 00 00 00 00 02 C3 0D
					39 01 00 00 00 00 03 F0 A5 A5

					/* OPLUS ADFR OFF */
					39 00 00 00 00 00 03 F0 5A 5A				/* Level2 key Access Enable */
					39 00 00 00 00 00 03 FC 5A 5A               /* Level3 key Access Enable */
					39 00 00 00 00 00 02 B9 00					/* TP shift fixed*/
					39 00 00 00 00 00 04 B0 00 02 60
					15 00 00 00 00 00 02 60 00					/* OPLUS ADFR off */
					39 00 00 00 00 00 03 F2 00 01               /* 0x01, 0x00 : ADFR ON setting, 0x00, 0x01 : ADFR OFF Setting */
					15 00 00 00 00 00 02 F7 0F
					39 00 00 00 00 00 03 FC A5 A5               /* Level3 key Access Disable */
					39 01 00 00 00 00 03 F0 A5 A5				/* Level2 key Access Disable */

					/* SDC ADFR */
					39 00 00 00 00 00 03 F0 5A 5A				/* Level2 key Access Enable */
					39 00 00 00 00 00 04 B0 00 22 B9			/* TSP_HSYNC Fixed TE*/
					15 00 00 00 00 00 02 B9 21
					39 00 00 00 00 00 04 B0 00 3A B9
					39 00 00 00 00 00 02 B9 02					/* TSP_HSYNC Fixed TE 02:120  03:90 05:60 */
					39 00 00 00 00 00 04 B0 00 16 F2
					39 00 00 00 00 00 03 F2 1B 50				/* 0x1B, 0x50 : 120hz,  0x24, 0x70 : 90hz */
					39 00 00 00 00 00 03 BD 21 02				/* 0x21, 0x02 : 120hz,  0x21, 0x03 : 90hz */
					15 00 00 00 00 00 02 60 00					/* 0x00 : 120hz,  0x08 : 90hz */
					15 00 00 00 00 00 02 F7 0F
					39 01 00 00 11 00 03 F0 A5 A5				/* Level2 key Access Disable, wait 17ms for TE stable*/

					39 00 00 00 00 00 03 F0 5A 5A				/* Level2 key Access Enable */
					15 00 00 00 00 00 02 BD 23					/* 21 : Manual On  23 Auto On */
					15 00 00 00 00 00 02 60 00					/* 0x00 : 120hz,  0x08 : 90hz */
					15 00 00 00 00 00 02 F7 0F
					39 01 00 00 00 00 03 F0 A5 A5				/* Level2 key Access Disable */
				];
				qcom,mdss-dsi-on-command = [
					/* PPS setting */
					39 01 00 00 0B 00 5A 9E
					11 00 00 89 30 80 0C 90
					05 A0 00 43 02 D0 02 D0
					02 00 02 C2 00 20 06 89
					00 0A 00 0F 01 D2 01 24
					18 00 10 F0 03 0C 20 00
					06 0B 0B 33 0E 1C 2A 38
					46 54 62 69 70 77 79 7B
					7D 7E 01 02 01 00 09 40
					09 BE 19 FC 19 FA 19 F8
					1A 38 1A 78 1A B6 2A B6
					2A F4 2A F4 4B 34 63 74 00
					/* DSC enable */
					15 01 00 00 00 00 02 9D 01
					/*Sleep out */
					05 01 00 00 07 00 01 11

					/* TSP_VSYNC Fixed 120Hz Setting */
					39 01 00 00 00 00 03 F0 5A 5A
					39 01 00 00 00 00 04 B0 00 22 B9
					15 01 00 00 00 00 02 B9 21
					39 01 00 00 00 00 04 B0 00 3A B9
					15 01 00 00 00 00 02 B9 02
					15 01 00 00 00 00 02 F7 0F
					39 01 00 00 78 00 03 F0 A5 A5

					/* SDC ADFR 120hz */
					39 01 00 00 00 00 03 F0 5A 5A				/* Level2 key Access Enable */
					39 01 00 00 00 00 04 B0 00 16 F2
					39 01 00 00 00 00 03 F2 1B 50				/* 0x1B, 0x50 : 120hz,  0x24, 0x70 : 90hz */
					39 01 00 00 00 00 03 BD 21 02				/* 0x21, 0x02 : 120hz,  0x21, 0x03 : 90hz */
					15 01 00 00 00 00 02 60 00					/* 0x00 : 120hz,  0x08 : 90hz */
					15 01 00 00 00 00 02 F7 0F
					39 01 00 00 00 00 03 F0 A5 A5				/* Level2 key Access Disable */

					/* SDC auto mode */
					39 01 00 00 00 00 03 F0 5A 5A				/* Level2 key Access Enable */
					15 01 00 00 00 00 02 BD 23					/* 21 : Manual On  23 Auto On */
					15 01 00 00 00 00 02 60 00					/* 0x00 : 120hz,  0x08 : 90hz */
					15 01 00 00 00 00 02 F7 0F
					39 01 00 00 00 00 03 F0 A5 A5				/* Level2 key Access Disable */

					/* Common Setting */
					/* FQ_CON Setting */
					39 01 00 00 00 00 03 F0 5A 5A				/* Level2 key Access Enable */
					39 01 00 00 00 00 03 F2 00 01				/* FQ_CON Setting */
					39 01 00 00 00 00 03 F0 A5 A5				/* Level2 key Access Disable */
					/* TE(Vsync) ON/OFF */
					15 01 00 00 00 00 02 35 00					/* TE On(Vsync) */

					/* Resolution setting */
					/* CASET/PASET Setting */
					39 01 00 00 00 00 05 2A 00 00 04 37
					39 01 00 00 00 00 05 2B 00 00 09 6B
					/* Scaler Setting */
					39 01 00 00 00 00 03 F0 5A 5A
					15 01 00 00 00 00 02 C3 0D
					39 01 00 00 00 00 03 F0 A5 A5

					/* Loading effect compensation Control */
					39 01 00 00 00 00 03 F0 5A 5A				/* TEST KEY Enable */
					39 01 00 00 00 00 04 B0 02 B6 1D				/* Global Para */
					15 01 00 00 00 00 02 1D 25					/* Loading effect compensation Setting, 0x25: mode ON, 0x05:mode ON */
					39 01 00 00 00 00 03 F0 A5 A5

					/* Brightness Control */
					/* Dimming Setting */
					39 01 00 00 00 00 03 F0 5A 5A				/* Level2 key Access Enable */
					39 01 00 00 00 00 04 B0 00 0D 63
					15 01 00 00 00 00 02 63 01					/* Dimming Speed Setting */
					39 01 00 00 00 00 04 B0 00 0C 63
					15 01 00 00 00 00 02 63 20					/* ELVSS Dim Setting */
					39 01 00 00 00 00 03 F0 A5 A5				/* Level2 key Access Disable */
					15 01 00 00 00 00 02 53 28					/* WRCTRLD */
					39 01 00 00 00 00 03 51 07 FF				/* WRDISBV */
					15 01 00 00 00 00 02 F7 0F

					/** OPEC ON ***/
					39 01 00 00 00 00 03 F0 5A 5A
					39 01 00 00 00 00 04 B0 00 52 1F
					39 01 00 00 00 00 02 1F 02
					39 01 00 00 00 00 04 B0 00 54 1F
					39 01 00 00 00 00 02 1F 01
					39 01 00 00 00 00 03 F0 A5 A5

					/** ACL off ***/
					39 01 00 00 00 00 03 F0 5A 5A
					15 01 00 00 00 00 02 55 00
					39 01 00 00 14 00 03 F0 A5 A5
					/* ELVSS DIM OFF  */
					39 01 00 00 00 00 03 F0 5A 5A
					39 01 00 00 00 00 04 B0 00 0C 63
					15 01 00 00 00 00 02 63 00
					39 01 00 00 00 00 03 F0 A5 A5

					/* Display On */
					//05 01 00 00 00 00 01 29
				];
				qcom,mdss-dsi-post-on-backlight = [
					/* Display On */
					05 01 00 00 00 00 01 29
				];
				qcom,mdss-dsi-off-command=[
					05 01 00 00 0A 00 02 28 00
					05 01 00 00 78 00 02 10 00
				];
				qcom,mdss-dsi-lp1-command = [
					//05 01 00 00 11 00 01 28
					/* AOD Mode ON Setting */
					39 01 00 00 00 00 03 F0 5A 5A
					15 01 00 00 00 00 02 53 24
					15 01 00 00 00 00 02 6A 00
					15 01 00 00 00 00 02 F7 0F
					15 01 00 00 00 00 02 49 01
					39 01 00 00 24 00 03 F0 A5 A5
					05 01 00 00 00 00 01 29
				];
				qcom,mdss-dsi-nolp-command = [
					/* AOD OFF */
					39 01 00 00 00 00 03 F0 5A 5A
					15 01 00 00 00 00 02 53 20
					15 01 00 00 00 00 02 F7 0F
					15 01 00 00 00 00 02 49 02
					39 01 00 00 00 00 03 F0 A5 A5
					/* SDC ADFR */
					39 00 00 00 00 00 03 F0 5A 5A				/* Level2 key Access Enable */
					39 00 00 00 00 00 04 B0 00 22 B9			/* TSP_HSYNC Fixed TE*/
					15 00 00 00 00 00 02 B9 21
					39 00 00 00 00 00 04 B0 00 3A B9
					39 00 00 00 00 00 02 B9 02					/* TSP_HSYNC Fixed TE 02:120  03:90 05:60 */
					39 00 00 00 00 00 04 B0 00 16 F2
					39 00 00 00 00 00 03 F2 1B 50				/* 0x1B, 0x50 : 120hz,  0x24, 0x70 : 90hz */
					39 00 00 00 00 00 03 BD 21 02				/* 0x21, 0x02 : 120hz,  0x21, 0x03 : 90hz */
					15 00 00 00 00 00 02 60 00					/* 0x00 : 120hz,  0x08 : 90hz */
					15 00 00 00 00 00 02 F7 0F
					39 01 00 00 11 00 03 F0 A5 A5				/* Level2 key Access Disable, wait 17ms for TE stable*/
					/* ELVSS DIM OFF  */
					39 01 00 00 00 00 03 F0 5A 5A
					39 01 00 00 00 00 04 B0 00 0C 63
					15 01 00 00 00 00 02 63 00
					39 01 00 00 00 00 03 F0 A5 A5
					/* Normal Mode */
					39 01 00 00 00 00 03 F0 5A 5A
					39 01 00 00 00 00 04 B0 00 01 49
					15 01 00 00 00 00 02 49 01
					15 01 00 00 00 00 02 53 20
					15 01 00 00 00 00 02 F7 0F
					39 01 00 00 00 00 03 F0 A5 A5
					/* AOR 16% */
					//39 01 00 00 00 00 03 F0 5A 5A
					//39 01 00 00 00 00 04 B0 00 01 BD
					//39 01 00 00 00 00 02 BD 02
					//39 01 00 00 00 00 04 B0 02 B9 65
					//39 01 00 00 00 00 07 65 01 5E 01 5E 01 5E
					//39 01 00 00 00 00 02 F7 0F
					//39 01 00 00 00 00 03 F0 A5 A5
				];
				qcom,mdss-dsi-aod-hbm-on-command = [
					/* Loading OFF */
					39 01 00 00 00 00 03 F0 5A 5A
					39 01 00 00 00 00 04 B0 02 B6 1D
					39 01 00 00 00 00 02 1D 05
					39 01 00 00 00 00 03 F0 A5 A5
					/* AOD OFF */
					39 01 00 00 00 00 03 F0 5A 5A
					39 01 00 00 00 00 02 53 20
					15 01 00 00 00 00 02 F7 0F
					15 01 00 00 00 00 02 49 02
					39 01 00 00 00 00 03 F0 A5 A5
					/* AOR 1.6% */
					39 01 00 00 00 00 03 F0 5A 5A
					39 01 00 00 00 00 04 B0 00 01 BD
					39 01 00 00 00 00 02 BD 00
					39 01 00 00 00 00 04 B0 02 B9 65
					39 01 00 00 00 00 07 65 00 AC 00 AC 00 AC
					39 01 00 00 00 00 02 F7 0F
					39 01 00 00 00 00 03 F0 A5 A5
					/* Hbm ON */
					39 01 00 00 00 00 03 F0 5A 5A
					39 01 00 00 00 00 04 B0 00 01 49
					39 01 00 00 00 00 02 49 00
					15 01 00 00 00 00 02 53 E0
					39 01 00 00 00 00 03 51 0B 7F
					15 01 00 00 00 00 02 F7 0F
					39 01 00 00 00 00 03 F0 A5 A5
				];
				qcom,mdss-dsi-aod-hbm-off-command = [
					/* HBM OFF */
					39 01 00 00 00 00 03 F0 5A 5A
					39 01 00 00 00 00 04 B0 00 01 49
					15 01 00 00 00 00 02 49 01
					15 01 00 00 00 00 02 53 20
					15 01 00 00 00 00 02 F7 0F
					39 01 00 00 00 00 03 F0 A5 A5
					/* AOD ON */
					39 01 00 00 00 00 03 F0 5A 5A
					15 01 00 00 00 00 02 53 24
					15 01 00 00 00 00 02 6A 00
					15 01 00 00 00 00 02 F7 0F
					39 01 00 00 00 00 02 49 01
					39 01 00 00 00 00 03 F0 A5 A5
				];
				qcom,mdss-dsi-hbm-off-command = [
					39 01 00 00 00 00 03 F0 5A 5A
					39 01 00 00 00 00 04 B0 00 01 49
					39 01 00 00 00 00 02 49 01
					15 01 00 00 00 00 02 53 20
					//39 01 00 00 05 00 03 51 05 14
					15 01 00 00 00 00 02 F7 0F
					39 01 00 00 00 00 03 F0 A5 A5
					/* Loading ON */
					//39 01 00 00 00 00 03 F0 5A 5A
					//39 01 00 00 00 00 04 B0 02 B6 1D
					//39 01 00 00 00 00 02 1D 25
					//39 01 00 00 00 00 03 F0 A5 A5
				];
				qcom,mdss-dsi-hbm-on-command = [
					/* Loading OFF */
					39 01 00 00 00 00 03 F0 5A 5A
					39 01 00 00 00 00 04 B0 02 B6 1D
					39 01 00 00 00 00 02 1D 05
					39 01 00 00 00 00 03 F0 A5 A5
					/* AOR 1.6% */
					39 01 00 00 00 00 03 F0 5A 5A
					39 01 00 00 00 00 04 B0 00 01 BD
					39 01 00 00 00 00 02 BD 00
					39 01 00 00 00 00 04 B0 02 B9 65
					39 01 00 00 00 00 07 65 00 AC 00 AC 00 AC
					39 01 00 00 00 00 02 F7 0F
					39 01 00 00 00 00 03 F0 A5 A5
					/* Hbm ON */
					39 01 00 00 00 00 03 F0 5A 5A
					39 01 00 00 00 00 04 B0 00 01 49
					39 01 00 00 00 00 02 49 00
					15 01 00 00 00 00 02 53 E0
					39 01 00 00 00 00 03 51 0B 7F
					15 01 00 00 00 00 02 F7 0F
					39 01 00 00 00 00 03 F0 A5 A5
				];
				qcom,mdss-dsi-normal-hbm-on-command = [
					/* Loading OFF */
					39 01 00 00 00 00 03 F0 5A 5A
					39 01 00 00 00 00 04 B0 02 B6 1D
					39 01 00 00 00 00 02 1D 05
					39 01 00 00 00 00 03 F0 A5 A5
					/* AOR 1.6% */
					39 01 00 00 00 00 03 F0 5A 5A
					39 01 00 00 00 00 04 B0 00 01 BD
					39 01 00 00 00 00 02 BD 00
					39 01 00 00 00 00 04 B0 02 B9 65
					39 01 00 00 00 00 07 65 00 AC 00 AC 00 AC
					39 01 00 00 00 00 02 F7 0F
					39 01 00 00 00 00 03 F0 A5 A5
					/* Hbm ON */
					39 01 00 00 00 00 03 F0 5A 5A
					39 01 00 00 00 00 04 B0 00 01 49
					39 01 00 00 00 00 02 49 00
					15 01 00 00 00 00 02 53 E0
					39 01 00 00 00 00 03 51 0B 7F
					15 01 00 00 00 00 02 F7 0F
					39 01 00 00 00 00 03 F0 A5 A5
				];
				qcom,mdss-dsi-aod-high-mode-command = [
					/* AOD 50nit */
					39 01 00 00 00 00 03 F0 5A 5A
					15 01 00 00 00 00 02 53 24
					39 01 00 00 00 00 02 6A 00
					39 01 00 00 00 00 03 F0 A5 A5
				];
				qcom,mdss-dsi-aod-low-mode-command = [
					/* AOD 10nit */
					39 01 00 00 00 00 03 F0 5A 5A
					15 01 00 00 00 00 02 53 27
					39 01 00 00 00 00 02 6A 00
					39 01 00 00 00 00 03 F0 A5 A5
				];
				qcom,mdss-dsi-seed-off-command = [
					/* SEED CRC OFF*/
					15 01 00 00 00 00 02 1C 00
					/* SEED CRC BYPASS */
					39 01 00 00 00 00 03 F0 5A 5A
					15 01 00 00 00 00 02 1D 01
					39 01 00 00 00 00 03 F0 A5 A5
				];
				qcom,mdss-dsi-seed-0-command = [
					/* SEED CRC Setting*/
					15 01 00 00 00 00 02 1C 05
					39 01 00 00 00 00 03 F0 5A 5A
					39 01 00 00 00 00 04 B0 00 01 1D
					/* SEED DCI-P3 Setting*/
					39 01 00 00 00 00 16 1D FF 00 00 00 FF 00 00 00 FF 00 FF FF FF 00 FF FF FF 00 FF FF FF
					15 01 00 00 00 00 02 1D 00
					39 01 00 00 00 00 03 F0 A5 A5
				];
				qcom,mdss-dsi-seed-1-command = [
					/* SEED CRC Setting*/
					15 01 00 00 00 00 02 1C 05
					39 01 00 00 00 00 03 F0 5A 5A
					39 01 00 00 00 00 04 B0 00 01 1D
					/* SEED DCI-P3 Setting*/
					39 01 00 00 00 00 16 1D FF 00 00 00 FF 00 00 00 FF 00 FF FF FF 00 FF FF FF 00 FF FF FF
					15 01 00 00 00 00 02 1D 00
					39 01 00 00 00 00 03 F0 A5 A5
				];
				qcom,mdss-dsi-seed-2-command = [
					/* SEED CRC Setting*/
					15 01 00 00 00 00 02 1C 05
					39 01 00 00 00 00 03 F0 5A 5A
					39 01 00 00 00 00 04 B0 00 01 1D
					/* SEED DCI-P3 Setting*/
					39 01 00 00 00 00 16 1D FF 00 00 00 FF 00 00 00 FF 00 FF FF FF 00 FF FF FF 00 FF FF FF
					15 01 00 00 00 00 02 1D 00
					39 01 00 00 00 00 03 F0 A5 A5
				];
				qcom,mdss-dsi-loading-effect-1-command = [
					39 01 00 00 00 00 03 F0 5A 5A
					39 01 00 00 00 00 04 B0 02 B6 1D
					39 01 00 00 00 00 02 1D 25
					39 01 00 00 00 00 04 B0 01 A5 1F
					39 01 00 00 00 00 09 1F E2 02 02 02 92 2C 6A 80
					39 01 00 00 00 00 04 B0 01 AD 1F
					39 01 00 00 00 00 07 1F 00 00 00 00 FF 90
					39 01 00 00 00 00 04 B0 01 B5 1F
					39 01 00 00 00 00 04 1F 49 00 10
					39 01 00 00 00 00 04 B0 01 BA 1F
					39 01 00 00 00 00 06 1F 05 FF 10 00 00
					39 01 00 00 00 00 04 B0 01 C1 1F
					39 01 00 00 00 00 03 1F 00 00
					39 01 00 00 00 00 04 B0 01 C5 1F
					39 01 00 00 00 00 05 1F 03 FF 21 3C
					39 01 00 00 00 00 03 F0 A5 A5
				];
				qcom,mdss-dsi-loading-effect-2-command = [
					39 01 00 00 00 00 03 F0 5A 5A
					39 01 00 00 00 00 04 B0 02 B6 1D
					39 01 00 00 00 00 02 1D 25
					39 01 00 00 00 00 04 B0 01 A5 1F
					39 01 00 00 00 00 09 1F E2 02 02 02 92 2C 6A 80
					39 01 00 00 00 00 04 B0 01 AD 1F
					39 01 00 00 00 00 07 1F 81 67 8F 72 FF 90
					39 01 00 00 00 00 04 B0 01 B5 1F
					39 01 00 00 00 00 04 1F 49 00 10
					39 01 00 00 00 00 04 B0 01 BA 1F
					39 01 00 00 00 00 06 1F 05 FF 10 00 00
					39 01 00 00 00 00 04 B0 01 C1 1F
					39 01 00 00 00 00 03 1F 00 00
					39 01 00 00 00 00 04 B0 01 C5 1F
					39 01 00 00 00 00 05 1F 03 FF 21 3C
					39 01 00 00 00 00 03 F0 A5 A5
				];
				qcom,mdss-dsi-loading-effect-off-command = [
					39 01 00 00 00 00 03 F0 5A 5A
					39 01 00 00 00 00 04 B0 02 B6 1D
					39 01 00 00 00 00 02 1D 05
					39 01 00 00 00 00 04 B0 01 A5 1F
					39 01 00 00 00 00 09 1F E2 02 02 02 92 2C 6A 80
					39 01 00 00 00 00 04 B0 01 AD 1F
					39 01 00 00 00 00 07 1F 71 27 4E 0B FF 9F
					39 01 00 00 00 00 04 B0 01 B5 1F
					39 01 00 00 00 00 04 1F 49 00 10
					39 01 00 00 00 00 04 B0 01 BA 1F
					39 01 00 00 00 00 06 1F 05 FF 10 00 00
					39 01 00 00 00 00 04 B0 01 C1 1F
					39 01 00 00 00 00 03 1F 00 00
					39 01 00 00 00 00 04 B0 01 C5 1F
					39 01 00 00 00 00 05 1F 03 FF 21 3C
					39 01 00 00 00 00 03 F0 A5 A5
				];
				qcom,mdss-dsi-aod-hbm-on-command-state = "dsi_hs_mode";
				qcom,mdss-dsi-aod-hbm-off-command-state = "dsi_hs_mode";
				qcom,mdss-dsi-timing-switch-command-state = "dsi_hs_mode";
				qcom,mdss-dsi-on-command-state = "dsi_lp_mode";
				qcom,mdss-dsi-off-command-state = "dsi_hs_mode";
				qcom,mdss-dsi-seed-off-command-state = "dsi_hs_mode";
				qcom,mdss-dsi-seed-0-command-state = "dsi_hs_mode";
				qcom,mdss-dsi-seed-1-command-state = "dsi_hs_mode";
				qcom,mdss-dsi-seed-2-command-state = "dsi_hs_mode";
				qcom,mdss-dsi-loading-effect-1-command-state = "dsi_hs_mode";
				qcom,mdss-dsi-loading-effect-2-command-state = "dsi_hs_mode";
				qcom,mdss-dsi-loading-effect-off-command-state = "dsi_hs_mode";
				qcom,mdss-dsi-hbm-on-command-state = "dsi_hs_mode";
				qcom,mdss-dsi-hbm-off-command-state = "dsi_hs_mode";

				qcom,compression-mode = "dsc";
				qcom,lm-split = <540 540>;
				qcom,mdss-dsc-encoders = <2>;
				qcom,mdss-dsc-slice-height = <36>;
				qcom,mdss-dsc-slice-width = <540>;
				qcom,mdss-dsc-slice-per-pkt = <2>;
				qcom,mdss-dsc-bit-per-component = <10>;
				qcom,mdss-dsc-bit-per-pixel = <8>;
				qcom,mdss-dsc-block-prediction-enable;
				qcom,mdss-dsi-panel-id1-command-state = "dsi_lp_mode";
				qcom,mdss-dsi-panel-read-register-open-state = "dsi_lp_mode";
				qcom,mdss-dsi-panel-read-register-close-state = "dsi_lp_mode";
			};
			timing@sdc_fhd_90{
				qcom,mdss-dsi-timing-default;
				qcom,mdss-mdp-transfer-time-us = <9000>;
				qcom,mdss-dsi-panel-framerate = <90>;
				qcom,mdss-dsi-panel-clockrate = <1452000000>;
				qcom,mdss-dsi-panel-width = <1080>;
				qcom,mdss-dsi-panel-height = <2412>;

				qcom,mdss-dsi-h-front-porch = <64>;
				qcom,mdss-dsi-h-back-porch = <48>;
				qcom,mdss-dsi-h-pulse-width = <8>;
				qcom,mdss-dsi-h-sync-skew = <0>;
				qcom,mdss-dsi-h-sync-pulse = <0>;
				qcom,mdss-dsi-v-back-porch = <1100>;
				qcom,mdss-dsi-v-front-porch = <1100>;
				qcom,mdss-dsi-v-pulse-width = <188>;
				qcom,mdss-dsi-h-left-border = <0>;
				qcom,mdss-dsi-h-right-border = <0>;
				qcom,mdss-dsi-v-top-border = <0>;
				qcom,mdss-dsi-v-bottom-border = <0>;

				qcom,dsi-select-clocks = "mux_byte_clk0", "mux_pixel_clk0";

				oplus,fod-on-vblank = <2>;
				oplus,fod-off-vblank = <3>;
				qcom,mdss-dsi-panel-read-register-open-command = [
					39 01 00 00 00 00 03 F0 5A 5A
					];
				qcom,mdss-dsi-panel-id1-command = [
					06 01 00 00 00 00 01 E9
					];
				qcom,mdss-dsi-panel-read-register-close-command = [
					39 01 00 00 00 00 03 F0 A5 A5
					];
				qcom,mdss-dsi-timing-switch-command = [
					/* Resolution setting */
					/* CASET/PASET Setting */
					39 01 00 00 00 00 05 2A 00 00 04 37
					39 01 00 00 00 00 05 2B 00 00 09 6B
					/* Scaler Setting */
					39 01 00 00 00 00 03 F0 5A 5A
					15 01 00 00 00 00 02 C3 0D
					39 01 00 00 00 00 03 F0 A5 A5

					/* OPLUS ADFR OFF */
					39 00 00 00 00 00 03 F0 5A 5A				/* Level2 key Access Enable */
					39 00 00 00 00 00 03 FC 5A 5A               /* Level3 key Access Enable */
					39 00 00 00 00 00 02 B9 00					/* TP shift fixed*/
					39 00 00 00 00 00 04 B0 00 02 60
					15 00 00 00 00 00 02 60 00					/* OPLUS ADFR off*/
					39 00 00 00 00 00 03 F2 00 01               /* 0x01, 0x00 : ADFR ON setting, 0x00, 0x01 : ADFR OFF Setting */
					15 00 00 00 00 00 02 F7 0F
					39 00 00 00 00 00 03 FC A5 A5               /* Level3 key Access Disable */
					39 01 00 00 00 00 03 F0 A5 A5				/* Level2 key Access Disable */

					/* SDC ADFR */
					39 00 00 00 00 00 03 F0 5A 5A				/* Level2 key Access Enable */
					39 00 00 00 00 00 04 B0 00 22 B9			/* TSP_HSYNC Fixed TE*/
					15 00 00 00 00 00 02 B9 21
					39 00 00 00 00 00 04 B0 00 3A B9
					39 00 00 00 00 00 02 B9 03					/* TSP_HSYNC Fixed TE 02:120  03:90 05:60 */
					39 00 00 00 00 00 04 B0 00 16 F2
					39 00 00 00 00 00 03 F2 24 70				/* 0x1B, 0x50 : 120hz,  0x24, 0x70 : 90hz */
					39 00 00 00 00 00 03 BD 21 03				/* 0x21, 0x02 : 120hz,  0x21, 0x03 : 90hz */
					15 00 00 00 00 00 02 60 08					/* 0x00 : 120hz,  0x08 : 90hz */
					15 00 00 00 00 00 02 F7 0F
					39 01 00 00 11 00 03 F0 A5 A5				/* Level2 key Access Disable, wait 17ms for TE stable*/

					39 00 00 00 00 00 03 F0 5A 5A				/* Level2 key Access Enable */
					15 00 00 00 00 00 02 BD 23					/* 21 : Manual On  23 Auto On */
					15 00 00 00 00 00 02 60 08					/* 0x00 : 120hz,  0x08 : 90hz */
					15 00 00 00 00 00 02 F7 0F
					39 01 00 00 00 00 03 F0 A5 A5				/* Level2 key Access Disable */
				];
				qcom,mdss-dsi-on-command = [
					/* PPS setting */
					39 01 00 00 0B 00 5A 9E
					11 00 00 89 30 80 0C 90
					05 A0 00 43 02 D0 02 D0
					02 00 02 C2 00 20 06 89
					00 0A 00 0F 01 D2 01 24
					18 00 10 F0 03 0C 20 00
					06 0B 0B 33 0E 1C 2A 38
					46 54 62 69 70 77 79 7B
					7D 7E 01 02 01 00 09 40
					09 BE 19 FC 19 FA 19 F8
					1A 38 1A 78 1A B6 2A B6
					2A F4 2A F4 4B 34 63 74 00
					/* DSC enable */
					15 01 00 00 00 00 02 9D 01
					/*Sleep out */
					05 01 00 00 07 00 01 11

					/* TSP_VSYNC Fixed 90hz Setting */
					39 00 00 00 00 00 03 F0 5A 5A
					39 00 00 00 00 00 04 B0 00 22 B9
					15 00 00 00 00 00 02 B9 21
					39 00 00 00 00 00 04 B0 00 3A B9
					15 00 00 00 00 00 02 B9 03					/* 02 : Fixed 120Hz TE 03 : Fixed 90Hz TE 05 : Fixed 60Hz TE*/
					15 00 00 00 00 00 02 F7 0F
					39 01 00 00 78 00 03 F0 A5 A5

					/* SDC ADFR 90hz */
					39 00 00 00 00 00 03 F0 5A 5A				/* Level2 key Access Enable */
					39 00 00 00 00 00 04 B0 00 16 F2
					39 00 00 00 00 00 03 F2 24 70				/* 0x1B, 0x50 : 120hz,  0x24, 0x70 : 90hz */
					39 00 00 00 00 00 03 BD 21 03				/* 0x21, 0x02 : 120hz,  0x21, 0x03 : 90hz */
					15 00 00 00 00 00 02 60 08					/* 0x00 : 120hz,  0x08 : 90hz */
					15 00 00 00 00 00 02 F7 0F
					39 01 00 00 00 00 03 F0 A5 A5				/* Level2 key Access Disable */

					/* SDC auto mode */
					39 00 00 00 00 00 03 F0 5A 5A				/* Level2 key Access Enable */
					15 00 00 00 00 00 02 BD 23					/* 21 : Manual On  23 Auto On */
					15 00 00 00 00 00 02 60 08					/* 0x00 : 120hz,  0x08 : 90hz */
					15 00 00 00 00 00 02 F7 0F
					39 01 00 00 00 00 03 F0 A5 A5				/* Level2 key Access Disable */

					/* Common Setting */
					/* FQ_CON Setting */
					39 01 00 00 00 00 03 F0 5A 5A				/* Level2 key Access Enable */
					39 01 00 00 00 00 03 F2 00 01				/* FQ_CON Setting */
					39 01 00 00 00 00 03 F0 A5 A5				/* Level2 key Access Disable */
					/* TE(Vsync) ON/OFF */
					15 01 00 00 00 00 02 35 00					/* TE On(Vsync)  00:on 01:off*/

					/* Resolution setting */
					/* CASET/PASET Setting */
					39 01 00 00 00 00 05 2A 00 00 04 37
					39 01 00 00 00 00 05 2B 00 00 09 6B
					/* Scaler Setting */
					39 01 00 00 00 00 03 F0 5A 5A
					15 01 00 00 00 00 02 C3 0D
					39 01 00 00 00 00 03 F0 A5 A5

					/* Loading effect compensation Control */
					39 01 00 00 00 00 03 F0 5A 5A				/* TEST KEY Enable */
					39 01 00 00 00 00 04 B0 02 B6 1D			/* Global Para */
					15 01 00 00 00 00 02 1D 25					/* Loading effect compensation Setting, 0x25: mode ON, 0x05:   mode ON */
					39 01 00 00 00 00 03 F0 A5 A5

					/* Brightness Control */
					/* Dimming Setting */
					39 01 00 00 00 00 03 F0 5A 5A				/* Level2 key Access Enable */
					39 01 00 00 00 00 04 B0 00 0D 63
					15 01 00 00 00 00 02 63 01					/* Dimming Speed Setting */
					39 01 00 00 00 00 04 B0 00 0C 63
					15 01 00 00 00 00 02 63 20					/* ELVSS Dim Setting */
					39 01 00 00 00 00 03 F0 A5 A5				/* Level2 key Access Disable */
					15 01 00 00 00 00 02 53 28					/* WRCTRLD */
					39 01 00 00 00 00 03 51 07 FF				/* WRDISBV */
					15 01 00 00 00 00 02 F7 0F

					/** OPEC ON ***/
					39 01 00 00 00 00 03 F0 5A 5A
					39 01 00 00 00 00 04 B0 00 52 1F
					39 01 00 00 00 00 02 1F 02
					39 01 00 00 00 00 04 B0 00 54 1F
					39 01 00 00 00 00 02 1F 01
					39 01 00 00 00 00 03 F0 A5 A5
					/** ACL off ***/
					39 01 00 00 00 00 03 F0 5A 5A
					15 01 00 00 00 00 02 55 00
					39 01 00 00 14 00 03 F0 A5 A5
					/* ELVSS DIM OFF  */
					39 01 00 00 00 00 03 F0 5A 5A
					39 01 00 00 00 00 04 B0 00 0C 63
					15 01 00 00 00 00 02 63 00
					39 01 00 00 00 00 03 F0 A5 A5
					//05 01 00 00 00 00 01 29
				];
				qcom,mdss-dsi-post-on-backlight = [
					/* Display On */
					05 01 00 00 00 00 01 29
				];
				qcom,mdss-dsi-off-command=[
					05 01 00 00 0A 00 02 28 00
					05 01 00 00 78 00 02 10 00
				];
				qcom,mdss-dsi-lp1-command = [
					//05 01 00 00 11 00 01 28
					/* AOD Mode ON Setting */
					39 01 00 00 00 00 03 F0 5A 5A
					15 01 00 00 00 00 02 53 24
					15 01 00 00 00 00 02 6A 00
					15 01 00 00 00 00 02 F7 0F
					15 01 00 00 00 00 02 49 01
					39 01 00 00 24 00 03 F0 A5 A5
					05 01 00 00 00 00 01 29
				];
				qcom,mdss-dsi-nolp-command = [
					/* AOD OFF */
					39 01 00 00 00 00 03 F0 5A 5A
					15 01 00 00 00 00 02 53 20
					15 01 00 00 00 00 02 F7 0F
					15 01 00 00 00 00 02 49 02
					39 01 00 00 00 00 03 F0 A5 A5
					/* SDC ADFR 90hz */
					39 00 00 00 00 00 03 F0 5A 5A				/* Level2 key Access Enable */
					39 00 00 00 00 00 04 B0 00 16 F2
					39 00 00 00 00 00 03 F2 24 70				/* 0x1B, 0x50 : 120hz,  0x24, 0x70 : 90hz */
					39 00 00 00 00 00 03 BD 21 03				/* 0x21, 0x02 : 120hz,  0x21, 0x03 : 90hz */
					15 00 00 00 00 00 02 60 08					/* 0x00 : 120hz,  0x08 : 90hz */
					15 00 00 00 00 00 02 F7 0F
					39 01 00 00 00 00 03 F0 A5 A5				/* Level2 key Access Disable */
					/* ELVSS DIM OFF  */
					39 01 00 00 00 00 03 F0 5A 5A
					39 01 00 00 00 00 04 B0 00 0C 63
					15 01 00 00 00 00 02 63 00
					39 01 00 00 00 00 03 F0 A5 A5
					/* Normal Mode */
					39 01 00 00 00 00 03 F0 5A 5A
					39 01 00 00 00 00 04 B0 00 01 49
					15 01 00 00 00 00 02 49 01
					15 01 00 00 00 00 02 53 20
					15 01 00 00 00 00 02 F7 0F
					39 01 00 00 00 00 03 F0 A5 A5
					/* AOR 16% */
					//39 01 00 00 00 00 03 F0 5A 5A
					//39 01 00 00 00 00 04 B0 00 01 BD
					//39 01 00 00 00 00 02 BD 02
					//39 01 00 00 00 00 04 B0 02 B9 65
					//39 01 00 00 00 00 07 65 01 5E 01 5E 01 5E
					//39 01 00 00 00 00 02 F7 0F
					//39 01 00 00 00 00 03 F0 A5 A5
				];
				qcom,mdss-dsi-aod-hbm-on-command = [
					/* Loading OFF */
					39 01 00 00 00 00 03 F0 5A 5A
					39 01 00 00 00 00 04 B0 02 B6 1D
					39 01 00 00 00 00 02 1D 05
					39 01 00 00 00 00 03 F0 A5 A5
					/* AOD OFF */
					39 01 00 00 00 00 03 F0 5A 5A
					39 01 00 00 00 00 02 53 20
					15 01 00 00 00 00 02 F7 0F
					15 01 00 00 00 00 02 49 02
					39 01 00 00 00 00 03 F0 A5 A5
					/* AOR 1.6% */
					39 01 00 00 00 00 03 F0 5A 5A
					39 01 00 00 00 00 04 B0 00 01 BD
					39 01 00 00 00 00 02 BD 00
					39 01 00 00 00 00 04 B0 02 B9 65
					39 01 00 00 00 00 07 65 00 AC 00 AC 00 AC
					39 01 00 00 00 00 02 F7 0F
					39 01 00 00 00 00 03 F0 A5 A5
					/* Hbm ON */
					39 01 00 00 00 00 03 F0 5A 5A
					39 01 00 00 00 00 04 B0 00 01 49
					39 01 00 00 00 00 02 49 00
					15 01 00 00 00 00 02 53 E0
					39 01 00 00 00 00 03 51 0B 7F
					15 01 00 00 00 00 02 F7 0F
					39 01 00 00 00 00 03 F0 A5 A5
				];
				qcom,mdss-dsi-aod-hbm-off-command = [
					/* HBM OFF */
					39 01 00 00 00 00 03 F0 5A 5A
					39 01 00 00 00 00 04 B0 00 01 49
					15 01 00 00 00 00 02 49 01
					15 01 00 00 00 00 02 53 20
					15 01 00 00 00 00 02 F7 0F
					39 01 00 00 00 00 03 F0 A5 A5
					/* AOD ON */
					39 01 00 00 00 00 03 F0 5A 5A
					15 01 00 00 00 00 02 53 24
					15 01 00 00 00 00 02 6A 00
					15 01 00 00 00 00 02 F7 0F
					39 01 00 00 00 00 02 49 01
					39 01 00 00 00 00 03 F0 A5 A5
				];
				qcom,mdss-dsi-hbm-off-command = [
					39 01 00 00 00 00 03 F0 5A 5A
					39 01 00 00 00 00 04 B0 00 01 49
					39 01 00 00 00 00 02 49 01
					15 01 00 00 00 00 02 53 20
					//39 01 00 00 05 00 03 51 05 14
					15 01 00 00 00 00 02 F7 0F
					39 01 00 00 00 00 03 F0 A5 A5
					/* Loading ON */
					//39 01 00 00 00 00 03 F0 5A 5A
					//39 01 00 00 00 00 04 B0 02 B6 1D
					//39 01 00 00 00 00 02 1D 25
					//39 01 00 00 00 00 03 F0 A5 A5
				];
				qcom,mdss-dsi-hbm-on-command = [
					/* Loading OFF */
					39 01 00 00 00 00 03 F0 5A 5A
					39 01 00 00 00 00 04 B0 02 B6 1D
					39 01 00 00 00 00 02 1D 05
					39 01 00 00 00 00 03 F0 A5 A5
					/* AOR 1.6% */
					39 01 00 00 00 00 03 F0 5A 5A
					39 01 00 00 00 00 04 B0 00 01 BD
					39 01 00 00 00 00 02 BD 00
					39 01 00 00 00 00 04 B0 02 B9 65
					39 01 00 00 00 00 07 65 00 AC 00 AC 00 AC
					39 01 00 00 00 00 02 F7 0F
					39 01 00 00 00 00 03 F0 A5 A5
					/* Hbm ON */
					39 01 00 00 00 00 03 F0 5A 5A
					39 01 00 00 00 00 04 B0 00 01 49
					39 01 00 00 00 00 02 49 00
					15 01 00 00 00 00 02 53 E0
					39 01 00 00 00 00 03 51 0B 7F
					15 01 00 00 00 00 02 F7 0F
					39 01 00 00 00 00 03 F0 A5 A5
				];
				qcom,mdss-dsi-normal-hbm-on-command = [
					/* Loading OFF */
					39 01 00 00 00 00 03 F0 5A 5A
					39 01 00 00 00 00 04 B0 02 B6 1D
					39 01 00 00 00 00 02 1D 05
					39 01 00 00 00 00 03 F0 A5 A5
					/* AOR 1.6% */
					39 01 00 00 00 00 03 F0 5A 5A
					39 01 00 00 00 00 04 B0 00 01 BD
					39 01 00 00 00 00 02 BD 00
					39 01 00 00 00 00 04 B0 02 B9 65
					39 01 00 00 00 00 07 65 00 AC 00 AC 00 AC
					39 01 00 00 00 00 02 F7 0F
					39 01 00 00 00 00 03 F0 A5 A5
					/* Hbm ON */
					39 01 00 00 00 00 03 F0 5A 5A
					39 01 00 00 00 00 04 B0 00 01 49
					39 01 00 00 00 00 02 49 00
					15 01 00 00 00 00 02 53 E0
					39 01 00 00 00 00 03 51 0B 7F
					15 01 00 00 00 00 02 F7 0F
					39 01 00 00 00 00 03 F0 A5 A5
				];
				qcom,mdss-dsi-aod-high-mode-command = [
					/* AOD 50nit */
					39 01 00 00 00 00 03 F0 5A 5A
					15 01 00 00 00 00 02 53 24
					39 01 00 00 00 00 02 6A 00
					39 01 00 00 00 00 03 F0 A5 A5
				];
				qcom,mdss-dsi-aod-low-mode-command = [
					/* AOD 10nit */
					39 01 00 00 00 00 03 F0 5A 5A
					15 01 00 00 00 00 02 53 27
					39 01 00 00 00 00 02 6A 00
					39 01 00 00 00 00 03 F0 A5 A5
				];
				qcom,mdss-dsi-seed-off-command = [
					/* SEED CRC OFF*/
					15 01 00 00 00 00 02 1C 00
					/* SEED CRC BYPASS */
					39 01 00 00 00 00 03 F0 5A 5A
					15 01 00 00 00 00 02 1D 01
					39 01 00 00 00 00 03 F0 A5 A5
				];
				qcom,mdss-dsi-seed-0-command = [
					/* SEED CRC Setting*/
					15 01 00 00 00 00 02 1C 05
					39 01 00 00 00 00 03 F0 5A 5A
					39 01 00 00 00 00 04 B0 00 01 1D
					/* SEED DCI-P3 Setting*/
					39 01 00 00 00 00 16 1D FF 00 00 00 FF 00 00 00 FF 00 FF FF FF 00 FF FF FF 00 FF FF FF
					15 01 00 00 00 00 02 1D 00
					39 01 00 00 00 00 03 F0 A5 A5
				];
				qcom,mdss-dsi-seed-1-command = [
					/* SEED CRC Setting*/
					15 01 00 00 00 00 02 1C 05
					39 01 00 00 00 00 03 F0 5A 5A
					39 01 00 00 00 00 04 B0 00 01 1D
					/* SEED DCI-P3 Setting*/
					39 01 00 00 00 00 16 1D FF 00 00 00 FF 00 00 00 FF 00 FF FF FF 00 FF FF FF 00 FF FF FF
					15 01 00 00 00 00 02 1D 00
					39 01 00 00 00 00 03 F0 A5 A5
				];
				qcom,mdss-dsi-seed-2-command = [
					/* SEED CRC Setting*/
					15 01 00 00 00 00 02 1C 05
					39 01 00 00 00 00 03 F0 5A 5A
					39 01 00 00 00 00 04 B0 00 01 1D
					/* SEED DCI-P3 Setting*/
					39 01 00 00 00 00 16 1D FF 00 00 00 FF 00 00 00 FF 00 FF FF FF 00 FF FF FF 00 FF FF FF
					15 01 00 00 00 00 02 1D 00
					39 01 00 00 00 00 03 F0 A5 A5
				];
				qcom,mdss-dsi-loading-effect-1-command = [
					39 01 00 00 00 00 03 F0 5A 5A
					39 01 00 00 00 00 04 B0 02 B6 1D
					39 01 00 00 00 00 02 1D 25
					39 01 00 00 00 00 04 B0 01 A5 1F
					39 01 00 00 00 00 09 1F E2 02 02 02 92 2C 6A 80
					39 01 00 00 00 00 04 B0 01 AD 1F
					39 01 00 00 00 00 07 1F 00 00 00 00 FF 90
					39 01 00 00 00 00 04 B0 01 B5 1F
					39 01 00 00 00 00 04 1F 49 00 10
					39 01 00 00 00 00 04 B0 01 BA 1F
					39 01 00 00 00 00 06 1F 05 FF 10 00 00
					39 01 00 00 00 00 04 B0 01 C1 1F
					39 01 00 00 00 00 03 1F 00 00
					39 01 00 00 00 00 04 B0 01 C5 1F
					39 01 00 00 00 00 05 1F 03 FF 21 3C
					39 01 00 00 00 00 03 F0 A5 A5
				];
				qcom,mdss-dsi-loading-effect-2-command = [
					39 01 00 00 00 00 03 F0 5A 5A
					39 01 00 00 00 00 04 B0 02 B6 1D
					39 01 00 00 00 00 02 1D 25
					39 01 00 00 00 00 04 B0 01 A5 1F
					39 01 00 00 00 00 09 1F E2 02 02 02 92 2C 6A 80
					39 01 00 00 00 00 04 B0 01 AD 1F
					39 01 00 00 00 00 07 1F 81 67 8F 72 FF 90
					39 01 00 00 00 00 04 B0 01 B5 1F
					39 01 00 00 00 00 04 1F 49 00 10
					39 01 00 00 00 00 04 B0 01 BA 1F
					39 01 00 00 00 00 06 1F 05 FF 10 00 00
					39 01 00 00 00 00 04 B0 01 C1 1F
					39 01 00 00 00 00 03 1F 00 00
					39 01 00 00 00 00 04 B0 01 C5 1F
					39 01 00 00 00 00 05 1F 03 FF 21 3C
					39 01 00 00 00 00 03 F0 A5 A5
				];
				qcom,mdss-dsi-loading-effect-off-command = [
					39 01 00 00 00 00 03 F0 5A 5A
					39 01 00 00 00 00 04 B0 02 B6 1D
					39 01 00 00 00 00 02 1D 05
					39 01 00 00 00 00 04 B0 01 A5 1F
					39 01 00 00 00 00 09 1F E2 02 02 02 92 2C 6A 80
					39 01 00 00 00 00 04 B0 01 AD 1F
					39 01 00 00 00 00 07 1F 71 27 4E 0B FF 9F
					39 01 00 00 00 00 04 B0 01 B5 1F
					39 01 00 00 00 00 04 1F 49 00 10
					39 01 00 00 00 00 04 B0 01 BA 1F
					39 01 00 00 00 00 06 1F 05 FF 10 00 00
					39 01 00 00 00 00 04 B0 01 C1 1F
					39 01 00 00 00 00 03 1F 00 00
					39 01 00 00 00 00 04 B0 01 C5 1F
					39 01 00 00 00 00 05 1F 03 FF 21 3C
					39 01 00 00 00 00 03 F0 A5 A5
				];
				qcom,mdss-dsi-aod-hbm-on-command-state = "dsi_hs_mode";
				qcom,mdss-dsi-aod-hbm-off-command-state = "dsi_hs_mode";
				qcom,mdss-dsi-timing-switch-command-state = "dsi_hs_mode";
				qcom,mdss-dsi-on-command-state = "dsi_lp_mode";
				qcom,mdss-dsi-off-command-state = "dsi_hs_mode";
				qcom,mdss-dsi-seed-off-command-state = "dsi_hs_mode";
				qcom,mdss-dsi-seed-0-command-state = "dsi_hs_mode";
				qcom,mdss-dsi-seed-1-command-state = "dsi_hs_mode";
				qcom,mdss-dsi-seed-2-command-state = "dsi_hs_mode";
				qcom,mdss-dsi-loading-effect-1-command-state = "dsi_hs_mode";
				qcom,mdss-dsi-loading-effect-2-command-state = "dsi_hs_mode";
				qcom,mdss-dsi-loading-effect-off-command-state = "dsi_hs_mode";
				qcom,mdss-dsi-hbm-on-command-state = "dsi_hs_mode";
				qcom,mdss-dsi-hbm-off-command-state = "dsi_hs_mode";

				qcom,compression-mode = "dsc";
				qcom,lm-split = <540 540>;
				qcom,mdss-dsc-encoders = <2>;
				qcom,mdss-dsc-slice-height = <36>;
				qcom,mdss-dsc-slice-width = <540>;
				qcom,mdss-dsc-slice-per-pkt = <2>;
				qcom,mdss-dsc-bit-per-component = <10>;
				qcom,mdss-dsc-bit-per-pixel = <8>;
				qcom,mdss-dsc-block-prediction-enable;
				qcom,mdss-dsi-panel-id1-command-state = "dsi_lp_mode";
				qcom,mdss-dsi-panel-read-register-open-state = "dsi_lp_mode";
				qcom,mdss-dsi-panel-read-register-close-state = "dsi_lp_mode";
			};
			// timing@sdc_wqhd_60{
			// 	//qcom,mdss-mdp-transfer-time-us = <12000>;
			// 	qcom,mdss-dsi-panel-jitter = <0x4 0x1>;
			// 	qcom,mdss-dsi-timing-default;
			// 	qcom,mdss-dsi-panel-framerate = <60>;
			// 	qcom,mdss-dsi-panel-clockrate = <1452000000>;
			// 	qcom,mdss-dsi-panel-width = <1440>;
			// 	qcom,mdss-dsi-panel-height = <3216>;

			// 	qcom,mdss-dsi-h-front-porch = <100>;
			// 	qcom,mdss-dsi-h-back-porch = <48>;
			// 	qcom,mdss-dsi-h-pulse-width = <12>;
			// 	qcom,mdss-dsi-h-sync-skew = <0>;
			// 	qcom,mdss-dsi-v-back-porch = <180>;
			// 	qcom,mdss-dsi-v-front-porch = <180>;
			// 	qcom,mdss-dsi-v-pulse-width = <20>;
			// 	qcom,mdss-dsi-h-sync-pulse = <0>;

			// 	qcom,mdss-dsi-h-left-border = <0>;
			// 	qcom,mdss-dsi-h-right-border = <0>;
			// 	qcom,mdss-dsi-v-top-border = <0>;
			// 	qcom,mdss-dsi-v-bottom-border = <0>;

			// 	qcom,dsi-select-clocks = "mux_byte_clk0", "mux_pixel_clk0";

			// 	oplus,fod-on-vblank = <1>;
			// 	oplus,fod-off-vblank = <0>;
			// 	qcom,mdss-dsi-panel-read-register-open-command = [
			// 		39 01 00 00 00 00 03 F0 5A 5A
			// 		];
			// 	qcom,mdss-dsi-panel-id1-command = [
			// 		06 01 00 00 00 00 01 E9
			// 		];
			// 	qcom,mdss-dsi-panel-read-register-close-command = [
			// 		39 01 00 00 00 00 03 F0 A5 A5
			// 		];
			// 	qcom,mdss-dsi-timing-switch-command = [
			// 		/* Resolution setting */
			// 		/* CASET/PASET Setting */
			// 		39 01 00 00 00 00 05 2A 00 00 05 9F
			// 		39 01 00 00 00 00 05 2B 00 00 0C 8F
			// 		/* Scaler Setting */
			// 		39 01 00 00 00 00 03 F0 5A 5A
			// 		15 01 00 00 00 00 02 C3 0C
			// 		39 01 00 00 00 00 03 F0 A5 A5

			// 		/* OPLUS ADFR OFF */
			// 		39 00 00 00 00 00 03 F0 5A 5A				/* Level2 key Access Enable */
			// 		39 00 00 00 00 00 03 FC 5A 5A               /* Level3 key Access Enable */
			// 		39 00 00 00 00 00 02 B9 00					/* TP shift fixed*/
			// 		39 00 00 00 00 00 04 B0 00 02 60
			// 		15 00 00 00 00 00 02 60 00					/* OPLUS ADFR off */
			// 		39 00 00 00 00 00 03 F2 00 01               /* 0x01, 0x00 : ADFR ON setting, 0x00, 0x01 : ADFR OFF Setting */
			// 		15 00 00 00 00 00 02 F7 0F
			// 		39 00 00 00 00 00 03 FC A5 A5               /* Level3 key Access Disable */
			// 		39 01 00 00 00 00 03 F0 A5 A5				/* Level2 key Access Disable */

			// 		/* SDC ADFR */
			// 		39 00 00 00 00 00 03 F0 5A 5A				/* Level2 key Access Enable */
			// 		39 00 00 00 00 00 04 B0 00 22 B9			/* TSP_HSYNC Fixed TE*/
			// 		15 00 00 00 00 00 02 B9 21
			// 		39 00 00 00 00 00 04 B0 00 3A B9
			// 		39 00 00 00 00 00 02 B9 05					/* TSP_HSYNC Fixed TE 02:120  03:90 05:60 */
			// 		39 00 00 00 00 00 04 B0 00 16 F2
			// 		39 00 00 00 00 00 03 F2 1B 50				/* 0x1B, 0x50 : 120hz,  0x24, 0x70 : 90hz */
			// 		39 00 00 00 00 00 03 BD 21 02				/* 0x21, 0x02 : 120hz,  0x21, 0x03 : 90hz */
			// 		15 00 00 00 00 00 02 60 01					/* 0x00 : 120hz,  0x08 : 90hz */
			// 		39 01 00 00 00 00 04 B0 00 10 BD
			// 		39 01 00 00 00 00 02 BD 00					/* HOP force off */
			// 		15 00 00 00 00 00 02 F7 0F
			// 		39 01 00 00 11 00 03 F0 A5 A5				/* Level2 key Access Disable, wait 17ms for TE stable*/
			// 	];
			// 	qcom,mdss-dsi-on-command = [
			// 		/* PPS setting */
			// 		39 01 00 00 0B 00 5A 9E
			// 		11 00 00 89 30 80 0C 90
			// 		05 A0 00 43 02 D0 02 D0
			// 		02 00 02 C2 00 20 06 89
			// 		00 0A 00 0F 01 D2 01 24
			// 		18 00 10 F0 03 0C 20 00
			// 		06 0B 0B 33 0E 1C 2A 38
			// 		46 54 62 69 70 77 79 7B
			// 		7D 7E 01 02 01 00 09 40
			// 		09 BE 19 FC 19 FA 19 F8
			// 		1A 38 1A 78 1A B6 2A B6
			// 		2A F4 2A F4 4B 34 63 74 00
			// 		/* DSC enable */
			// 		15 01 00 00 00 00 02 9D 01
			// 		/*Sleep out */
			// 		05 01 00 00 07 00 01 11

			// 		/* TSP_VSYNC Fixed 60Hz Setting */
			// 		39 01 00 00 00 00 03 F0 5A 5A
			// 		39 01 00 00 00 00 04 B0 00 22 B9
			// 		15 01 00 00 00 00 02 B9 21
			// 		39 01 00 00 00 00 04 B0 00 3A B9
			// 		15 01 00 00 00 00 02 B9 05					/* TSP_HSYNC Fixed TE 02:120  03:90 05:60 */
			// 		15 01 00 00 00 00 02 F7 0F
			// 		39 01 00 00 78 00 03 F0 A5 A5

			// 		/* SDC ADFR 60hz Transition */
			// 		39 01 00 00 00 00 03 F0 5A 5A				/* Level2 key Access Enable */
			// 		39 01 00 00 00 00 04 B0 00 16 F2
			// 		39 01 00 00 00 00 03 F2 1B 50				/* 0x1B, 0x50 : 120hz,  0x24, 0x70 : 90hz */
			// 		39 01 00 00 00 00 03 BD 21 02				/* 0x21 -> manual 23 -> auto,  02 -> 120hz 03 -> 90hz */
			// 		15 01 00 00 00 00 02 60 01					/* max fps for manual mode, 00 -> 120hz, 08 -> 120hz, 01 -> 60hz*/
			// 		39 01 00 00 00 00 04 B0 00 10 BD
			// 		39 01 00 00 00 00 02 BD 00					/* HOP force off */
			// 		15 01 00 00 00 00 02 F7 0F
			// 		39 01 00 00 00 00 03 F0 A5 A5				/* Level2 key Access Disable */

			// 		/* Common Setting */
			// 		/* FQ_CON Setting */
			// 		39 01 00 00 00 00 03 F0 5A 5A				/* Level2 key Access Enable */
			// 		39 01 00 00 00 00 03 F2 00 01				/* FQ_CON Setting */
			// 		39 01 00 00 00 00 03 F0 A5 A5				/* Level2 key Access Disable */
			// 		/* TE(Vsync) ON/OFF */
			// 		15 01 00 00 00 00 02 35 00					/* TE On(Vsync) */

			// 		/* Resolution setting */
			// 		/* CASET/PASET Setting */
			// 		39 01 00 00 00 00 05 2A 00 00 05 9F
			// 		39 01 00 00 00 00 05 2B 00 00 0C 8F
			// 		/* Scaler Setting */
			// 		39 01 00 00 00 00 03 F0 5A 5A
			// 		15 01 00 00 00 00 02 C3 0C
			// 		39 01 00 00 00 00 03 F0 A5 A5

			// 		/* Loading effect compensation Control */
			// 		39 01 00 00 00 00 03 F0 5A 5A				/* TEST KEY Enable */
			// 		39 01 00 00 00 00 04 B0 02 B6 1D				/* Global Para */
			// 		15 01 00 00 00 00 02 1D 25					/* Loading effect compensation Setting, 0x25: mode ON, 0x05:mode ON */
			// 		39 01 00 00 00 00 03 F0 A5 A5

			// 		/* Brightness Control */
			// 		/* Dimming Setting */
			// 		39 01 00 00 00 00 03 F0 5A 5A				/* Level2 key Access Enable */
			// 		39 01 00 00 00 00 04 B0 00 0D 63
			// 		15 01 00 00 00 00 02 63 01					/* Dimming Speed Setting */
			// 		39 01 00 00 00 00 04 B0 00 0C 63
			// 		15 01 00 00 00 00 02 63 20					/* ELVSS Dim Setting */
			// 		39 01 00 00 00 00 03 F0 A5 A5				/* Level2 key Access Disable */
			// 		15 01 00 00 00 00 02 53 28					/* WRCTRLD */
			// 		39 01 00 00 00 00 03 51 07 FF				/* WRDISBV */
			// 		15 01 00 00 00 00 02 F7 0F

			// 		/** OPEC ON ***/
			// 		39 01 00 00 00 00 03 F0 5A 5A
			// 		39 01 00 00 00 00 04 B0 00 52 1F
			// 		39 01 00 00 00 00 02 1F 02
			// 		39 01 00 00 00 00 04 B0 00 54 1F
			// 		39 01 00 00 00 00 02 1F 01
			// 		39 01 00 00 00 00 03 F0 A5 A5

			// 		/* ACL Mode */
			// 		39 01 00 00 00 00 03 F0 5A 5A				/* Level2 key Access Enable */
			// 		15 01 00 00 00 00 02 55 00					/* WRCABC, 0x00 : ACL Off */
			// 		39 01 00 00 00 00 03 F0 A5 A5				/* Level2 key Access Disable */

			// 		/* display on */
			// 		05 01 00 00 00 00 01 29
			// 	];
			// 	qcom,mdss-dsi-post-on-backlight = [
			// 		/* Display On */
			// 		05 01 00 00 00 00 01 29
			// 	];
			// 	qcom,mdss-dsi-off-command=[
			// 		05 01 00 00 0A 00 02 28 00
			// 		05 01 00 00 78 00 02 10 00
			// 	];
			// 	qcom,mdss-dsi-lp1-command = [
			// 		05 01 00 00 11 00 01 28
			// 		/* AOD Mode ON Setting */
			// 		39 01 00 00 00 00 03 F0 5A 5A
			// 		15 01 00 00 00 00 02 53 24
			// 		15 01 00 00 00 00 02 6A 00
			// 		15 01 00 00 00 00 02 F7 0F
			// 		15 01 00 00 00 00 02 49 01
			// 		39 01 00 00 14 00 03 F0 A5 A5
			// 		05 01 00 00 00 00 01 29
			// 	];
			// 	qcom,mdss-dsi-nolp-command = [
			// 		/* AOD OFF */
			// 		39 01 00 00 00 00 03 F0 5A 5A
			// 		15 01 00 00 00 00 02 53 20
			// 		15 01 00 00 00 00 02 F7 0F
			// 		15 01 00 00 00 00 02 49 02
			// 		39 01 00 00 00 00 03 F0 A5 A5
			// 		/* Normal Mode */
			// 		39 01 00 00 00 00 03 F0 5A 5A
			// 		39 01 00 00 00 00 04 B0 00 01 49
			// 		15 01 00 00 00 00 02 49 29
			// 		15 01 00 00 00 00 02 53 20
			// 		15 01 00 00 00 00 02 F7 0F
			// 		39 01 00 00 00 00 03 F0 A5 A5
			// 	];
			// 	qcom,mdss-dsi-aod-hbm-on-command = [
			// 		/* Loading OFF */
			// 		39 01 00 00 00 00 03 F0 5A 5A
			// 		39 01 00 00 00 00 04 B0 02 B6 1D
			// 		39 01 00 00 00 00 02 1D 05
			// 		39 01 00 00 00 00 03 F0 A5 A5
			// 		/* Hbm ON */
			// 		39 01 00 00 00 00 03 F0 5A 5A
			// 		39 01 00 00 00 00 04 B0 00 01 49
			// 		39 01 00 00 00 00 02 49 00
			// 		15 01 00 00 00 00 02 53 E0
			// 		39 01 00 00 00 00 03 51 0A FF
			// 		15 01 00 00 00 00 02 F7 0F
			// 		39 01 00 00 00 00 03 F0 A5 A5
			// 		/* AOR 1.6% */
			// 		39 01 00 00 00 00 03 F0 5A 5A
			// 		39 01 00 00 00 00 04 B0 00 01 BD
			// 		39 01 00 00 00 00 02 BD 00
			// 		39 01 00 00 00 00 04 B0 02 B9 65
			// 		39 01 00 00 00 00 07 65 00 6C 00 6C 00 6C
			// 		39 01 00 00 00 00 02 F7 0F
			// 		39 01 00 00 00 00 03 F0 A5 A5
			// 	];
			// 	qcom,mdss-dsi-aod-hbm-off-command = [
			// 		39 01 00 00 00 00 03 F0 5A 5A
			// 		39 01 00 00 00 00 04 B0 00 01 49
			// 		39 01 00 00 00 00 02 49 01
			// 		15 01 00 00 00 00 02 53 24
			// 		39 01 00 00 00 00 03 51 00 01
			// 		15 01 00 00 00 00 02 F7 0F
			// 		39 01 00 00 00 00 03 F0 A5 A5
			// 	];
			// 	qcom,mdss-dsi-hbm-off-command = [
			// 		39 01 00 00 00 00 03 F0 5A 5A
			// 		39 01 00 00 00 00 04 B0 00 01 49
			// 		39 01 00 00 00 00 02 49 01
			// 		15 01 00 00 00 00 02 53 20
			// 		15 01 00 00 00 00 02 F7 0F
			// 		39 01 00 00 00 00 03 F0 A5 A5
			// 		/* Loading ON */
			// 		39 01 00 00 00 00 03 F0 5A 5A
			// 		39 01 00 00 00 00 04 B0 02 B6 1D
			// 		39 01 00 00 00 00 02 1D 25
			// 		39 01 00 00 00 00 03 F0 A5 A5
			// 	];
			// 	qcom,mdss-dsi-hbm-on-command = [
			// 		/* Loading OFF */
			// 		39 01 00 00 00 00 03 F0 5A 5A
			// 		39 01 00 00 00 00 04 B0 02 B6 1D
			// 		39 01 00 00 00 00 02 1D 05
			// 		39 01 00 00 00 00 03 F0 A5 A5
			// 		/* Hbm ON */
			// 		39 01 00 00 00 00 03 F0 5A 5A
			// 		39 01 00 00 00 00 04 B0 00 01 49
			// 		39 01 00 00 00 00 02 49 00
			// 		15 01 00 00 00 00 02 53 E0
			// 		39 01 00 00 00 00 03 51 0A FF
			// 		15 01 00 00 00 00 02 F7 0F
			// 		39 01 00 00 00 00 03 F0 A5 A5
			// 		/* AOR 1.6% */
			// 		39 01 00 00 00 00 03 F0 5A 5A
			// 		39 01 00 00 00 00 04 B0 00 01 BD
			// 		39 01 00 00 00 00 02 BD 00
			// 		39 01 00 00 00 00 04 B0 02 B9 65
			// 		39 01 00 00 00 00 07 65 00 6C 00 6C 00 6C
			// 		39 01 00 00 00 00 02 F7 0F
			// 		39 01 00 00 00 00 03 F0 A5 A5
			// 	];
			// 	qcom,mdss-dsi-normal-hbm-on-command = [
			// 		/* Loading OFF */
			// 		39 01 00 00 00 00 03 F0 5A 5A
			// 		39 01 00 00 00 00 04 B0 02 B6 1D
			// 		39 01 00 00 00 00 02 1D 05
			// 		39 01 00 00 00 00 03 F0 A5 A5
			// 		/* Hbm ON */
			// 		39 01 00 00 00 00 03 F0 5A 5A
			// 		39 01 00 00 00 00 04 B0 00 01 49
			// 		39 01 00 00 00 00 02 49 00
			// 		15 01 00 00 00 00 02 53 E0
			// 		39 01 00 00 00 00 03 51 0A FF
			// 		15 01 00 00 00 00 02 F7 0F
			// 		39 01 00 00 00 00 03 F0 A5 A5
			// 		/* AOR 1.6% */
			// 		39 01 00 00 00 00 03 F0 5A 5A
			// 		39 01 00 00 00 00 04 B0 00 01 BD
			// 		39 01 00 00 00 00 02 BD 00
			// 		39 01 00 00 00 00 04 B0 02 B9 65
			// 		39 01 00 00 00 00 07 65 00 6C 00 6C 00 6C
			// 		39 01 00 00 00 00 02 F7 0F
			// 		39 01 00 00 00 00 03 F0 A5 A5
			// 	];
			// 	qcom,mdss-dsi-aod-high-mode-command = [
			// 		/* AOD 50nit */
			// 		39 01 00 00 00 00 03 F0 5A 5A
			// 		15 01 00 00 00 00 02 53 24
			// 		39 01 00 00 00 00 02 6A 00
			// 		39 01 00 00 00 00 03 F0 A5 A5
			// 	];
			// 	qcom,mdss-dsi-aod-low-mode-command = [
			// 		/* AOD 10nit */
			// 		39 01 00 00 00 00 03 F0 5A 5A
			// 		15 01 00 00 00 00 02 53 27
			// 		39 01 00 00 00 00 02 6A 00
			// 		39 01 00 00 00 00 03 F0 A5 A5
			// 	];
			// 	qcom,mdss-dsi-seed-off-command = [
			// 		/* SEED CRC OFF*/
			// 		15 01 00 00 00 00 02 1C 00
			// 		/* SEED CRC BYPASS */
			// 		39 01 00 00 00 00 03 F0 5A 5A
			// 		15 01 00 00 00 00 02 1D 01
			// 		39 01 00 00 00 00 03 F0 A5 A5
			// 	];
			// 	qcom,mdss-dsi-seed-0-command = [
			// 		/* SEED CRC Setting*/
			// 		15 01 00 00 00 00 02 1C 05
			// 		39 01 00 00 00 00 03 F0 5A 5A
			// 		39 01 00 00 00 00 04 B0 00 01 1D
			// 		/* SEED DCI-P3 Setting*/
			// 		39 01 00 00 00 00 16 1D FF 00 00 00 FF 00 00 00 FF 00 FF FF FF 00 FF FF FF 00 FF FF FF
			// 		15 01 00 00 00 00 02 1D 00
			// 		39 01 00 00 00 00 03 F0 A5 A5
			// 	];
			// 	qcom,mdss-dsi-seed-1-command = [
			// 		/* SEED CRC Setting*/
			// 		15 01 00 00 00 00 02 1C 05
			// 		39 01 00 00 00 00 03 F0 5A 5A
			// 		39 01 00 00 00 00 04 B0 00 01 1D
			// 		/* SEED DCI-P3 Setting*/
			// 		39 01 00 00 00 00 16 1D FF 00 00 00 FF 00 00 00 FF 00 FF FF FF 00 FF FF FF 00 FF FF FF
			// 		15 01 00 00 00 00 02 1D 00
			// 		39 01 00 00 00 00 03 F0 A5 A5
			// 	];
			// 	qcom,mdss-dsi-seed-2-command = [
			// 		/* SEED CRC Setting*/
			// 		15 01 00 00 00 00 02 1C 05
			// 		39 01 00 00 00 00 03 F0 5A 5A
			// 		39 01 00 00 00 00 04 B0 00 01 1D
			// 		/* SEED DCI-P3 Setting*/
			// 		39 01 00 00 00 00 16 1D FF 00 00 00 FF 00 00 00 FF 00 FF FF FF 00 FF FF FF 00 FF FF FF
			// 		15 01 00 00 00 00 02 1D 00
			// 		39 01 00 00 00 00 03 F0 A5 A5
			// 	];
			// 	qcom,mdss-dsi-loading-effect-1-command = [
			// 		39 01 00 00 00 00 03 F0 5A 5A
			// 		39 01 00 00 00 00 04 B0 02 B6 1D
			// 		39 01 00 00 00 00 02 1D 25
			// 		39 01 00 00 00 00 04 B0 01 A5 1F
			// 		39 01 00 00 00 00 09 1F E2 02 02 02 92 2C 6A 80
			// 		39 01 00 00 00 00 04 B0 01 AD 1F
			// 		39 01 00 00 00 00 07 1F 00 00 00 00 FF 90
			// 		39 01 00 00 00 00 04 B0 01 B5 1F
			// 		39 01 00 00 00 00 04 1F 49 00 10
			// 		39 01 00 00 00 00 04 B0 01 BA 1F
			// 		39 01 00 00 00 00 06 1F 05 FF 10 00 00
			// 		39 01 00 00 00 00 04 B0 01 C1 1F
			// 		39 01 00 00 00 00 03 1F 00 00
			// 		39 01 00 00 00 00 04 B0 01 C5 1F
			// 		39 01 00 00 00 00 05 1F 03 FF 21 3C
			// 		39 01 00 00 00 00 03 F0 A5 A5
			// 	];
			// 	qcom,mdss-dsi-loading-effect-2-command = [
			// 		39 01 00 00 00 00 03 F0 5A 5A
			// 		39 01 00 00 00 00 04 B0 02 B6 1D
			// 		39 01 00 00 00 00 02 1D 25
			// 		39 01 00 00 00 00 04 B0 01 A5 1F
			// 		39 01 00 00 00 00 09 1F E2 02 02 02 92 2C 6A 80
			// 		39 01 00 00 00 00 04 B0 01 AD 1F
			// 		39 01 00 00 00 00 07 1F 81 67 8F 72 FF 90
			// 		39 01 00 00 00 00 04 B0 01 B5 1F
			// 		39 01 00 00 00 00 04 1F 49 00 10
			// 		39 01 00 00 00 00 04 B0 01 BA 1F
			// 		39 01 00 00 00 00 06 1F 05 FF 10 00 00
			// 		39 01 00 00 00 00 04 B0 01 C1 1F
			// 		39 01 00 00 00 00 03 1F 00 00
			// 		39 01 00 00 00 00 04 B0 01 C5 1F
			// 		39 01 00 00 00 00 05 1F 03 FF 21 3C
			// 		39 01 00 00 00 00 03 F0 A5 A5
			// 	];
			// 	qcom,mdss-dsi-loading-effect-off-command = [
			// 		39 01 00 00 00 00 03 F0 5A 5A
			// 		39 01 00 00 00 00 04 B0 02 B6 1D
			// 		39 01 00 00 00 00 02 1D 05
			// 		39 01 00 00 00 00 04 B0 01 A5 1F
			// 		39 01 00 00 00 00 09 1F E2 02 02 02 92 2C 6A 80
			// 		39 01 00 00 00 00 04 B0 01 AD 1F
			// 		39 01 00 00 00 00 07 1F 71 27 4E 0B FF 9F
			// 		39 01 00 00 00 00 04 B0 01 B5 1F
			// 		39 01 00 00 00 00 04 1F 49 00 10
			// 		39 01 00 00 00 00 04 B0 01 BA 1F
			// 		39 01 00 00 00 00 06 1F 05 FF 10 00 00
			// 		39 01 00 00 00 00 04 B0 01 C1 1F
			// 		39 01 00 00 00 00 03 1F 00 00
			// 		39 01 00 00 00 00 04 B0 01 C5 1F
			// 		39 01 00 00 00 00 05 1F 03 FF 21 3C
			// 		39 01 00 00 00 00 03 F0 A5 A5
			// 	];
			// 	qcom,mdss-dsi-aod-hbm-on-command-state = "dsi_hs_mode";
			// 	qcom,mdss-dsi-aod-hbm-off-command-state = "dsi_hs_mode";
			// 	qcom,mdss-dsi-timing-switch-command-state = "dsi_hs_mode";
			// 	qcom,mdss-dsi-on-command-state = "dsi_lp_mode";
			// 	qcom,mdss-dsi-off-command-state = "dsi_hs_mode";
			// 	qcom,mdss-dsi-seed-off-command-state = "dsi_hs_mode";
			// 	qcom,mdss-dsi-seed-0-command-state = "dsi_hs_mode";
			// 	qcom,mdss-dsi-seed-1-command-state = "dsi_hs_mode";
			// 	qcom,mdss-dsi-seed-2-command-state = "dsi_hs_mode";
			// 	qcom,mdss-dsi-loading-effect-1-command-state = "dsi_hs_mode";
			// 	qcom,mdss-dsi-loading-effect-2-command-state = "dsi_hs_mode";
			// 	qcom,mdss-dsi-loading-effect-off-command-state = "dsi_hs_mode";
			// 	qcom,mdss-dsi-hbm-on-command-state = "dsi_hs_mode";
			// 	qcom,mdss-dsi-hbm-off-command-state = "dsi_hs_mode";

			// 	qcom,compression-mode = "dsc";
			// 	qcom,lm-split = <720 720>;
			// 	qcom,mdss-dsc-encoders = <2>;
			// 	qcom,mdss-dsc-slice-height = <67>;
			// 	qcom,mdss-dsc-slice-width = <720>;
			// 	qcom,mdss-dsc-slice-per-pkt = <2>;
			// 	qcom,mdss-dsc-bit-per-component = <8>;
			// 	qcom,mdss-dsc-bit-per-pixel = <8>;
			// 	qcom,mdss-dsc-block-prediction-enable;
			// 	qcom,mdss-dsi-panel-id1-command-state = "dsi_lp_mode";
			// 	qcom,mdss-dsi-panel-read-register-open-state = "dsi_lp_mode";
			// 	qcom,mdss-dsi-panel-read-register-close-state = "dsi_lp_mode";
			// };
			// timing@sdc_fhd_60{
			// 	//qcom,mdss-mdp-transfer-time-us = <14000>;
			// 	qcom,mdss-dsi-panel-jitter = <0x4 0x1>;
			// 	qcom,mdss-dsi-timing-default;
			// 	qcom,mdss-dsi-panel-framerate = <60>;
			// 	qcom,mdss-dsi-panel-clockrate = <1004000000>;
			// 	qcom,mdss-dsi-panel-width = <1080>;
			// 	qcom,mdss-dsi-panel-height = <2412>;

			// 	qcom,mdss-dsi-h-front-porch = <100>;
			// 	qcom,mdss-dsi-h-back-porch = <48>;
			// 	qcom,mdss-dsi-h-pulse-width = <12>;
			// 	qcom,mdss-dsi-h-sync-skew = <0>;
			// 	qcom,mdss-dsi-v-back-porch = <1100>;
			// 	qcom,mdss-dsi-v-front-porch = <1100>;
			// 	qcom,mdss-dsi-v-pulse-width = <20>;
			// 	qcom,mdss-dsi-h-sync-pulse = <0>;

			// 	qcom,mdss-dsi-h-left-border = <0>;
			// 	qcom,mdss-dsi-h-right-border = <0>;
			// 	qcom,mdss-dsi-v-top-border = <0>;
			// 	qcom,mdss-dsi-v-bottom-border = <0>;

			// 	qcom,dsi-select-clocks = "mux_byte_clk0", "mux_pixel_clk0";

			// 	oplus,fod-on-vblank = <1>;
			// 	oplus,fod-off-vblank = <0>;
			// 	qcom,mdss-dsi-panel-read-register-open-command = [
			// 		39 01 00 00 00 00 03 F0 5A 5A
			// 		];
			// 	qcom,mdss-dsi-panel-id1-command = [
			// 		06 01 00 00 00 00 01 E9
			// 		];
			// 	qcom,mdss-dsi-panel-read-register-close-command = [
			// 		39 01 00 00 00 00 03 F0 A5 A5
			// 		];
			// 	qcom,mdss-dsi-timing-switch-command = [
			// 		/* Resolution setting */
			// 		/* CASET/PASET Setting */
			// 		39 01 00 00 00 00 05 2A 00 00 04 37
			// 		39 01 00 00 00 00 05 2B 00 00 09 6B
			// 		/* Scaler Setting */
			// 		39 01 00 00 00 00 03 F0 5A 5A
			// 		15 01 00 00 00 00 02 C3 0D
			// 		39 01 00 00 00 00 03 F0 A5 A5

			// 		/* OPLUS ADFR OFF */
			// 		39 00 00 00 00 00 03 F0 5A 5A				/* Level2 key Access Enable */
			// 		39 00 00 00 00 00 03 FC 5A 5A               /* Level3 key Access Enable */
			// 		39 00 00 00 00 00 02 B9 00					/* TP shift fixed*/
			// 		39 00 00 00 00 00 04 B0 00 02 60
			// 		15 00 00 00 00 00 02 60 00					/* OPLUS ADFR off */
			// 		39 00 00 00 00 00 03 F2 00 01               /* 0x01, 0x00 : ADFR ON setting, 0x00, 0x01 : ADFR OFF Setting */
			// 		15 00 00 00 00 00 02 F7 0F
			// 		39 00 00 00 00 00 03 FC A5 A5               /* Level3 key Access Disable */
			// 		39 01 00 00 00 00 03 F0 A5 A5				/* Level2 key Access Disable */

			// 		/* SDC ADFR */
			// 		39 00 00 00 00 00 03 F0 5A 5A				/* Level2 key Access Enable */
			// 		39 00 00 00 00 00 04 B0 00 22 B9			/* TSP_HSYNC Fixed TE*/
			// 		15 00 00 00 00 00 02 B9 21
			// 		39 00 00 00 00 00 04 B0 00 3A B9
			// 		39 00 00 00 00 00 02 B9 05					/* TSP_HSYNC Fixed TE 02:120  03:90 05:60 */
			// 		39 00 00 00 00 00 04 B0 00 16 F2
			// 		39 00 00 00 00 00 03 F2 1B 50				/* 0x1B, 0x50 : 120hz,  0x24, 0x70 : 90hz */
			// 		39 00 00 00 00 00 03 BD 21 02				/* 0x21, 0x02 : 120hz,  0x21, 0x03 : 90hz */
			// 		15 00 00 00 00 00 02 60 01					/* 0x00 : 120hz,  0x08 : 90hz */
			// 		39 01 00 00 00 00 04 B0 00 10 BD
			// 		39 01 00 00 00 00 02 BD 00					/* HOP force off */
			// 		15 00 00 00 00 00 02 F7 0F
			// 		39 01 00 00 11 00 03 F0 A5 A5				/* Level2 key Access Disable, wait 17ms for TE stable*/
			// 	];
			// 	qcom,mdss-dsi-on-command = [
			// 		/* PPS setting */
			// 		39 01 00 00 0B 00 5A 9E
			// 		11 00 00 89 30 80 0C 90
			// 		05 A0 00 43 02 D0 02 D0
			// 		02 00 02 C2 00 20 06 89
			// 		00 0A 00 0F 01 D2 01 24
			// 		18 00 10 F0 03 0C 20 00
			// 		06 0B 0B 33 0E 1C 2A 38
			// 		46 54 62 69 70 77 79 7B
			// 		7D 7E 01 02 01 00 09 40
			// 		09 BE 19 FC 19 FA 19 F8
			// 		1A 38 1A 78 1A B6 2A B6
			// 		2A F4 2A F4 4B 34 63 74 00
			// 		/* DSC enable */
			// 		15 01 00 00 00 00 02 9D 01
			// 		/*Sleep out */
			// 		05 01 00 00 07 00 01 11

			// 		/* TSP_VSYNC Fixed 60Hz Setting */
			// 		39 01 00 00 00 00 03 F0 5A 5A
			// 		39 01 00 00 00 00 04 B0 00 22 B9
			// 		15 01 00 00 00 00 02 B9 21
			// 		39 01 00 00 00 00 04 B0 00 3A B9
			// 		15 01 00 00 00 00 02 B9 05					/* TSP_HSYNC Fixed TE 02:120  03:90 05:60 */
			// 		15 01 00 00 00 00 02 F7 0F
			// 		39 01 00 00 78 00 03 F0 A5 A5

			// 		/* SDC ADFR 60hz Transition */
			// 		39 01 00 00 00 00 03 F0 5A 5A				/* Level2 key Access Enable */
			// 		39 01 00 00 00 00 04 B0 00 16 F2
			// 		39 01 00 00 00 00 03 F2 1B 50				/* 0x1B, 0x50 : 120hz,  0x24, 0x70 : 90hz */
			// 		39 01 00 00 00 00 03 BD 21 02				/* 0x21 -> manual 23 -> auto,  02 -> 120hz 03 -> 90hz */
			// 		15 01 00 00 00 00 02 60 01					/* max fps for manual mode, 00 -> 120hz, 08 -> 120hz, 01 -> 60hz*/
			// 		39 01 00 00 00 00 04 B0 00 10 BD
			// 		39 01 00 00 00 00 02 BD 00					/* HOP force off */
			// 		15 01 00 00 00 00 02 F7 0F
			// 		39 01 00 00 00 00 03 F0 A5 A5				/* Level2 key Access Disable */

			// 		/* Common Setting */
			// 		/* FQ_CON Setting */
			// 		39 01 00 00 00 00 03 F0 5A 5A				/* Level2 key Access Enable */
			// 		39 01 00 00 00 00 03 F2 00 01				/* FQ_CON Setting */
			// 		39 01 00 00 00 00 03 F0 A5 A5				/* Level2 key Access Disable */
			// 		/* TE(Vsync) ON/OFF */
			// 		15 01 00 00 00 00 02 35 00					/* TE On(Vsync) */

			// 		/* Resolution setting */
			// 		/* CASET/PASET Setting */
			// 		39 01 00 00 00 00 05 2A 00 00 04 37
			// 		39 01 00 00 00 00 05 2B 00 00 09 6B
			// 		/* Scaler Setting */
			// 		39 01 00 00 00 00 03 F0 5A 5A
			// 		15 01 00 00 00 00 02 C3 0D
			// 		39 01 00 00 00 00 03 F0 A5 A5

			// 		/* Loading effect compensation Control */
			// 		39 01 00 00 00 00 03 F0 5A 5A				/* TEST KEY Enable */
			// 		39 01 00 00 00 00 04 B0 02 B6 1D				/* Global Para */
			// 		15 01 00 00 00 00 02 1D 25					/* Loading effect compensation Setting, 0x25: mode ON, 0x05:mode ON */
			// 		39 01 00 00 00 00 03 F0 A5 A5

			// 		/* Brightness Control */
			// 		/* Dimming Setting */
			// 		39 01 00 00 00 00 03 F0 5A 5A				/* Level2 key Access Enable */
			// 		39 01 00 00 00 00 04 B0 00 0D 63
			// 		15 01 00 00 00 00 02 63 01					/* Dimming Speed Setting */
			// 		39 01 00 00 00 00 04 B0 00 0C 63
			// 		15 01 00 00 00 00 02 63 20					/* ELVSS Dim Setting */
			// 		39 01 00 00 00 00 03 F0 A5 A5				/* Level2 key Access Disable */
			// 		15 01 00 00 00 00 02 53 28					/* WRCTRLD */
			// 		39 01 00 00 00 00 03 51 07 FF				/* WRDISBV */
			// 		15 01 00 00 00 00 02 F7 0F

			// 		/** OPEC ON ***/
			// 		39 01 00 00 00 00 03 F0 5A 5A
			// 		39 01 00 00 00 00 04 B0 00 52 1F
			// 		39 01 00 00 00 00 02 1F 02
			// 		39 01 00 00 00 00 04 B0 00 54 1F
			// 		39 01 00 00 00 00 02 1F 01
			// 		39 01 00 00 00 00 03 F0 A5 A5

			// 		/* ACL Mode */
			// 		39 01 00 00 00 00 03 F0 5A 5A				/* Level2 key Access Enable */
			// 		15 01 00 00 00 00 02 55 00					/* WRCABC, 0x00 : ACL Off */
			// 		39 01 00 00 00 00 03 F0 A5 A5				/* Level2 key Access Disable */

			// 		/* display on */
			// 		05 01 00 00 00 00 01 29
			// 	];
			// 	qcom,mdss-dsi-post-on-backlight = [
			// 		/* Display On */
			// 		05 01 00 00 00 00 01 29
			// 	];
			// 	qcom,mdss-dsi-off-command=[
			// 		05 01 00 00 0A 00 02 28 00
			// 		05 01 00 00 78 00 02 10 00
			// 	];
			// 	qcom,mdss-dsi-lp1-command = [
			// 		/* Panle OFF */
			// 		05 01 00 00 11 00 01 28
			// 		/* AOD Mode ON Setting */
			// 		39 01 00 00 00 00 03 F0 5A 5A
			// 		15 01 00 00 00 00 02 53 24
			// 		15 01 00 00 00 00 02 6A 00
			// 		15 01 00 00 00 00 02 F7 0F
			// 		15 01 00 00 00 00 02 49 01
			// 		39 01 00 00 14 00 03 F0 A5 A5
			// 		05 01 00 00 00 00 01 29
			// 	];
			// 	qcom,mdss-dsi-nolp-command = [
			// 		/* AOD OFF */
			// 		39 01 00 00 00 00 03 F0 5A 5A
			// 		15 01 00 00 00 00 02 53 20
			// 		15 01 00 00 00 00 02 F7 0F
			// 		15 01 00 00 00 00 02 49 02
			// 		39 01 00 00 00 00 03 F0 A5 A5
			// 		/* Normal Mode */
			// 		39 01 00 00 00 00 03 F0 5A 5A
			// 		39 01 00 00 00 00 04 B0 00 01 49
			// 		15 01 00 00 00 00 02 49 29
			// 		15 01 00 00 00 00 02 53 20
			// 		15 01 00 00 00 00 02 F7 0F
			// 		39 01 00 00 00 00 03 F0 A5 A5
			// 	];
			// 	qcom,mdss-dsi-aod-hbm-on-command = [
			// 		/* Loading OFF */
			// 		39 01 00 00 00 00 03 F0 5A 5A
			// 		39 01 00 00 00 00 04 B0 02 B6 1D
			// 		39 01 00 00 00 00 02 1D 05
			// 		39 01 00 00 00 00 03 F0 A5 A5
			// 		/* Hbm ON */
			// 		39 01 00 00 00 00 03 F0 5A 5A
			// 		39 01 00 00 00 00 04 B0 00 01 49
			// 		39 01 00 00 00 00 02 49 00
			// 		15 01 00 00 00 00 02 53 E0
			// 		39 01 00 00 00 00 03 51 0A FF
			// 		15 01 00 00 00 00 02 F7 0F
			// 		39 01 00 00 00 00 03 F0 A5 A5
			// 		/* AOR 1.6% */
			// 		39 01 00 00 00 00 03 F0 5A 5A
			// 		39 01 00 00 00 00 04 B0 00 01 BD
			// 		39 01 00 00 00 00 02 BD 00
			// 		39 01 00 00 00 00 04 B0 02 B9 65
			// 		39 01 00 00 00 00 07 65 00 6C 00 6C 00 6C
			// 		39 01 00 00 00 00 02 F7 0F
			// 		39 01 00 00 00 00 03 F0 A5 A5
			// 	];
			// 	qcom,mdss-dsi-aod-hbm-off-command = [
			// 		39 01 00 00 00 00 03 F0 5A 5A
			// 		39 01 00 00 00 00 04 B0 00 01 49
			// 		39 01 00 00 00 00 02 49 01
			// 		15 01 00 00 00 00 02 53 24
			// 		39 01 00 00 00 00 03 51 00 01
			// 		15 01 00 00 00 00 02 F7 0F
			// 		39 01 00 00 00 00 03 F0 A5 A5
			// 	];
			// 	qcom,mdss-dsi-hbm-off-command = [
			// 		39 01 00 00 00 00 03 F0 5A 5A
			// 		39 01 00 00 00 00 04 B0 00 01 49
			// 		39 01 00 00 00 00 02 49 01
			// 		15 01 00 00 00 00 02 53 20
			// 		15 01 00 00 00 00 02 F7 0F
			// 		39 01 00 00 00 00 03 F0 A5 A5
			// 		/* Loading ON */
			// 		39 01 00 00 00 00 03 F0 5A 5A
			// 		39 01 00 00 00 00 04 B0 02 B6 1D
			// 		39 01 00 00 00 00 02 1D 25
			// 		39 01 00 00 00 00 03 F0 A5 A5
			// 	];
			// 	qcom,mdss-dsi-hbm-on-command = [
			// 		/* Loading OFF */
			// 		39 01 00 00 00 00 03 F0 5A 5A
			// 		39 01 00 00 00 00 04 B0 02 B6 1D
			// 		39 01 00 00 00 00 02 1D 05
			// 		39 01 00 00 00 00 03 F0 A5 A5
			// 		/* Hbm ON */
			// 		39 01 00 00 00 00 03 F0 5A 5A
			// 		39 01 00 00 00 00 04 B0 00 01 49
			// 		39 01 00 00 00 00 02 49 00
			// 		15 01 00 00 00 00 02 53 E0
			// 		39 01 00 00 00 00 03 51 0A FF
			// 		15 01 00 00 00 00 02 F7 0F
			// 		39 01 00 00 00 00 03 F0 A5 A5
			// 		/* AOR 1.6% */
			// 		39 01 00 00 00 00 03 F0 5A 5A
			// 		39 01 00 00 00 00 04 B0 00 01 BD
			// 		39 01 00 00 00 00 02 BD 00
			// 		39 01 00 00 00 00 04 B0 02 B9 65
			// 		39 01 00 00 00 00 07 65 00 6C 00 6C 00 6C
			// 		39 01 00 00 00 00 02 F7 0F
			// 		39 01 00 00 00 00 03 F0 A5 A5
			// 	];
			// 	qcom,mdss-dsi-normal-hbm-on-command = [
			// 		/* Loading OFF */
			// 		39 01 00 00 00 00 03 F0 5A 5A
			// 		39 01 00 00 00 00 04 B0 02 B6 1D
			// 		39 01 00 00 00 00 02 1D 05
			// 		39 01 00 00 00 00 03 F0 A5 A5
			// 		/* Hbm ON */
			// 		39 01 00 00 00 00 03 F0 5A 5A
			// 		39 01 00 00 00 00 04 B0 00 01 49
			// 		39 01 00 00 00 00 02 49 00
			// 		15 01 00 00 00 00 02 53 E0
			// 		39 01 00 00 00 00 03 51 0A FF
			// 		15 01 00 00 00 00 02 F7 0F
			// 		39 01 00 00 00 00 03 F0 A5 A5
			// 		/* AOR 1.6% */
			// 		39 01 00 00 00 00 03 F0 5A 5A
			// 		39 01 00 00 00 00 04 B0 00 01 BD
			// 		39 01 00 00 00 00 02 BD 00
			// 		39 01 00 00 00 00 04 B0 02 B9 65
			// 		39 01 00 00 00 00 07 65 00 6C 00 6C 00 6C
			// 		39 01 00 00 00 00 02 F7 0F
			// 		39 01 00 00 00 00 03 F0 A5 A5
			// 	];
			// 	qcom,mdss-dsi-aod-high-mode-command = [
			// 		/* AOD 50nit */
			// 		39 01 00 00 00 00 03 F0 5A 5A
			// 		15 01 00 00 00 00 02 53 24
			// 		39 01 00 00 00 00 02 6A 00
			// 		39 01 00 00 00 00 03 F0 A5 A5
			// 	];
			// 	qcom,mdss-dsi-aod-low-mode-command = [
			// 		/* AOD 10nit */
			// 		39 01 00 00 00 00 03 F0 5A 5A
			// 		15 01 00 00 00 00 02 53 27
			// 		39 01 00 00 00 00 02 6A 00
			// 		39 01 00 00 00 00 03 F0 A5 A5
			// 	];
			// 	qcom,mdss-dsi-seed-off-command = [
			// 		/* SEED CRC OFF*/
			// 		15 01 00 00 00 00 02 1C 00
			// 		/* SEED CRC BYPASS */
			// 		39 01 00 00 00 00 03 F0 5A 5A
			// 		15 01 00 00 00 00 02 1D 01
			// 		39 01 00 00 00 00 03 F0 A5 A5
			// 	];
			// 	qcom,mdss-dsi-seed-0-command = [
			// 		/* SEED CRC Setting*/
			// 		15 01 00 00 00 00 02 1C 05
			// 		39 01 00 00 00 00 03 F0 5A 5A
			// 		39 01 00 00 00 00 04 B0 00 01 1D
			// 		/* SEED DCI-P3 Setting*/
			// 		39 01 00 00 00 00 16 1D FF 00 00 00 FF 00 00 00 FF 00 FF FF FF 00 FF FF FF 00 FF FF FF
			// 		15 01 00 00 00 00 02 1D 00
			// 		39 01 00 00 00 00 03 F0 A5 A5
			// 	];
			// 	qcom,mdss-dsi-seed-1-command = [
			// 		/* SEED CRC Setting*/
			// 		15 01 00 00 00 00 02 1C 05
			// 		39 01 00 00 00 00 03 F0 5A 5A
			// 		39 01 00 00 00 00 04 B0 00 01 1D
			// 		/* SEED DCI-P3 Setting*/
			// 		39 01 00 00 00 00 16 1D FF 00 00 00 FF 00 00 00 FF 00 FF FF FF 00 FF FF FF 00 FF FF FF
			// 		15 01 00 00 00 00 02 1D 00
			// 		39 01 00 00 00 00 03 F0 A5 A5
			// 	];
			// 	qcom,mdss-dsi-seed-2-command = [
			// 		/* SEED CRC Setting*/
			// 		15 01 00 00 00 00 02 1C 05
			// 		39 01 00 00 00 00 03 F0 5A 5A
			// 		39 01 00 00 00 00 04 B0 00 01 1D
			// 		/* SEED DCI-P3 Setting*/
			// 		39 01 00 00 00 00 16 1D FF 00 00 00 FF 00 00 00 FF 00 FF FF FF 00 FF FF FF 00 FF FF FF
			// 		15 01 00 00 00 00 02 1D 00
			// 		39 01 00 00 00 00 03 F0 A5 A5
			// 	];
			// 	qcom,mdss-dsi-loading-effect-1-command = [
			// 		39 01 00 00 00 00 03 F0 5A 5A
			// 		39 01 00 00 00 00 04 B0 02 B6 1D
			// 		39 01 00 00 00 00 02 1D 25
			// 		39 01 00 00 00 00 04 B0 01 A5 1F
			// 		39 01 00 00 00 00 09 1F E2 02 02 02 92 2C 6A 80
			// 		39 01 00 00 00 00 04 B0 01 AD 1F
			// 		39 01 00 00 00 00 07 1F 00 00 00 00 FF 90
			// 		39 01 00 00 00 00 04 B0 01 B5 1F
			// 		39 01 00 00 00 00 04 1F 49 00 10
			// 		39 01 00 00 00 00 04 B0 01 BA 1F
			// 		39 01 00 00 00 00 06 1F 05 FF 10 00 00
			// 		39 01 00 00 00 00 04 B0 01 C1 1F
			// 		39 01 00 00 00 00 03 1F 00 00
			// 		39 01 00 00 00 00 04 B0 01 C5 1F
			// 		39 01 00 00 00 00 05 1F 03 FF 21 3C
			// 		39 01 00 00 00 00 03 F0 A5 A5
			// 	];
			// 	qcom,mdss-dsi-loading-effect-2-command = [
			// 		39 01 00 00 00 00 03 F0 5A 5A
			// 		39 01 00 00 00 00 04 B0 02 B6 1D
			// 		39 01 00 00 00 00 02 1D 25
			// 		39 01 00 00 00 00 04 B0 01 A5 1F
			// 		39 01 00 00 00 00 09 1F E2 02 02 02 92 2C 6A 80
			// 		39 01 00 00 00 00 04 B0 01 AD 1F
			// 		39 01 00 00 00 00 07 1F 81 67 8F 72 FF 90
			// 		39 01 00 00 00 00 04 B0 01 B5 1F
			// 		39 01 00 00 00 00 04 1F 49 00 10
			// 		39 01 00 00 00 00 04 B0 01 BA 1F
			// 		39 01 00 00 00 00 06 1F 05 FF 10 00 00
			// 		39 01 00 00 00 00 04 B0 01 C1 1F
			// 		39 01 00 00 00 00 03 1F 00 00
			// 		39 01 00 00 00 00 04 B0 01 C5 1F
			// 		39 01 00 00 00 00 05 1F 03 FF 21 3C
			// 		39 01 00 00 00 00 03 F0 A5 A5
			// 	];
			// 	qcom,mdss-dsi-loading-effect-off-command = [
			// 		39 01 00 00 00 00 03 F0 5A 5A
			// 		39 01 00 00 00 00 04 B0 02 B6 1D
			// 		39 01 00 00 00 00 02 1D 05
			// 		39 01 00 00 00 00 04 B0 01 A5 1F
			// 		39 01 00 00 00 00 09 1F E2 02 02 02 92 2C 6A 80
			// 		39 01 00 00 00 00 04 B0 01 AD 1F
			// 		39 01 00 00 00 00 07 1F 71 27 4E 0B FF 9F
			// 		39 01 00 00 00 00 04 B0 01 B5 1F
			// 		39 01 00 00 00 00 04 1F 49 00 10
			// 		39 01 00 00 00 00 04 B0 01 BA 1F
			// 		39 01 00 00 00 00 06 1F 05 FF 10 00 00
			// 		39 01 00 00 00 00 04 B0 01 C1 1F
			// 		39 01 00 00 00 00 03 1F 00 00
			// 		39 01 00 00 00 00 04 B0 01 C5 1F
			// 		39 01 00 00 00 00 05 1F 03 FF 21 3C
			// 		39 01 00 00 00 00 03 F0 A5 A5
			// 	];
			// 	qcom,mdss-dsi-aod-hbm-on-command-state = "dsi_hs_mode";
			// 	qcom,mdss-dsi-aod-hbm-off-command-state = "dsi_hs_mode";
			// 	qcom,mdss-dsi-timing-switch-command-state = "dsi_hs_mode";
			// 	qcom,mdss-dsi-on-command-state = "dsi_lp_mode";
			// 	qcom,mdss-dsi-off-command-state = "dsi_hs_mode";
			// 	qcom,mdss-dsi-seed-off-command-state = "dsi_hs_mode";
			// 	qcom,mdss-dsi-seed-0-command-state = "dsi_hs_mode";
			// 	qcom,mdss-dsi-seed-1-command-state = "dsi_hs_mode";
			// 	qcom,mdss-dsi-seed-2-command-state = "dsi_hs_mode";
			// 	qcom,mdss-dsi-loading-effect-1-command-state = "dsi_hs_mode";
			// 	qcom,mdss-dsi-loading-effect-2-command-state = "dsi_hs_mode";
			// 	qcom,mdss-dsi-loading-effect-off-command-state = "dsi_hs_mode";
			// 	qcom,mdss-dsi-hbm-on-command-state = "dsi_hs_mode";
			// 	qcom,mdss-dsi-hbm-off-command-state = "dsi_hs_mode";

			// 	qcom,lm-split = <540 540>;
			// 	qcom,compression-mode = "dsc";
			// 	qcom,mdss-dsc-encoders = <2>;
			// 	qcom,mdss-dsc-slice-height = <36>;
			// 	qcom,mdss-dsc-slice-width = <540>;
			// 	qcom,mdss-dsc-slice-per-pkt = <2>;
			// 	qcom,mdss-dsc-bit-per-component = <10>;
			// 	qcom,mdss-dsc-bit-per-pixel = <8>;
			// 	qcom,mdss-dsc-block-prediction-enable;
			// 	qcom,mdss-dsi-panel-id1-command-state = "dsi_lp_mode";
			// 	qcom,mdss-dsi-panel-read-register-open-state = "dsi_lp_mode";
			// 	qcom,mdss-dsi-panel-read-register-close-state = "dsi_lp_mode";
			// };
		};
	};
};

&dsi_oplus20061_samsung_1440_3216_dsc_cmd_evt {
	qcom,panel-supply-entries = <&dsi_panel_pwr_supply>;
	qcom,mdss-dsi-bl-pmic-control-type = "bl_ctrl_dcs";
	qcom,mdss-dsi-dc-backlight-level = <520>;
	qcom,mdss-dsi-bl-min-level = <1>;
	qcom,mdss-dsi-bl-normal-max-level = <2047>;
	qcom,mdss-dsi-bl-max-level = <4095>;
	qcom,mdss-brightness-normal-max-level = <2047>;
	qcom,mdss-brightness-max-level = <4095>;
	qcom,mdss-brightness-default-level = <400>;
	qcom,platform-te-gpio = <&tlmm 66 0>;
	qcom,platform-reset-gpio = <&tlmm 75 0>;
	qcom,platform-panel-vout-gpio = <&tlmm 8 0>;
	qcom,platform-panel-te-esd-gpio = <&tlmm 109 0>;
	qcom,platform-panel-vddr-aod-en-gpio = <&tlmm 139 0>;
	qcom,ulps-enabled;
	qcom,dsi-select-clocks = "mux_byte_clk0", "mux_pixel_clk0";

	oplus,dsi-fod-brightness = <0 0xff>,
			<2 0xef>,
			<4 0xee>,
			<5 0xed>,
			<6 0xed>,
			<7 0xec>,
			<8 0xeb>,
			<10 0xea>,
			<15 0xe8>,
			<20 0xe6>,
			<30 0xe0>,
			<40 0xdc>,
			<50 0xd9>,
			<70 0xd3>,
			<90 0xce>,
			<110 0xc9>,
			<140 0xc2>,
			<180 0xbc>,
			<220 0xb4>,
			<270 0xad>,
			<330 0xa4>,
			<400 0x9c>,
			<470 0x96>,
			<550 0x8e>,
			<630 0x88>,
			<720 0x7f>,
			<810 0x78>,
			<900 0x73>,
			<1000 0x6b>,
			<1150 0x61>,
			<1300 0x56>,
			<1500 0x4c>,
			<1700 0x42>,
			<1900 0x36>,
			<2047 0x2f>;

	oplus,dsi-dc-brightness = <0 0xff>,
			<1 0xfc>,
			<4 0xfb>,
			<6 0xfa>,
			<8 0xf9>,
			<10 0xf8>,
			<12 0xf7>,
			<14 0xf6>,
			<20 0xf4>,
			<30 0xf0>,
			<40 0xea>,
			<60 0xe0>,
			<90 0xd0>,
			<140 0xbc>,
			<200 0x98>,
			<240 0x80>,
			<280 0x70>,
			<320 0x58>,
			<360 0x48>,
			<400 0x30>,
			<440 0x20>,
			<480 0x10>,
			<520 0x00>;

	qcom,mdss-dsi-display-timings {
		timing@sdc_wqhd_120 { /* WQHD+ 120hz 726Mhz 1452Mbps */
			qcom,mdss-dsi-panel-phy-timings = [00 14 0C 0C 1F 27 05 05 03 02 04 00 12 15];
			qcom,display-topology = <1 1 1>,<2 2 1>;
			qcom,default-topology-index = <1>;
		};
		timing@sdc_wqhd_90 { /* WQHD+ 90hz 726Mhz 1452Mbps */
			qcom,mdss-dsi-panel-phy-timings = [00 2F 0C 0C 2A 27 0C 0D 09 02 04 00 26 1B];
			qcom,display-topology = <1 1 1>,<2 2 1>;
			qcom,default-topology-index = <1>;
		};
		timing@sdc_fhd_120 { /* FHD+ 120hz 726Mhz 1452Mbps */
			qcom,mdss-dsi-panel-phy-timings = [00 16 0C 0C 1F 27 05 05 03 02 04 00 12 15];
			qcom,display-topology = <1 1 1>,<2 2 1>;
			qcom,default-topology-index = <1>;
		};
		timing@sdc_fhd_90 { /* FHD+ 90hz 726Mhz 1452Mbps */
			qcom,mdss-dsi-panel-phy-timings = [00 1C 0C 0C 23 22 07 07 05 02 04 00 18 17];
			qcom,display-topology = <1 1 1>,<2 2 1>;
			qcom,default-topology-index = <1>;
		};
		// timing@sdc_wqhd_60 { /* WQHD+ 60hz 502Mhz 1004Mbps */
		// 	qcom,mdss-dsi-panel-phy-timings = [00 1C 07 07 23 23 07 07 05 02 04 00 18 1B];
		// 	qcom,display-topology = <1 1 1>,<2 2 1>;
		// 	qcom,default-topology-index = <1>;
		// };
		// timing@sdc_fhd_60 { /* FHD+ 60hz 502Mhz 1004Mbps */
		// 	qcom,mdss-dsi-panel-phy-timings = [00 1C 06 07 23 21 07 07 05 02 04 00 18 17];
		// 	qcom,display-topology = <1 1 1>,<2 2 1>;
		// 	qcom,default-topology-index = <1>;
		// };
	};
};
&dsi_oplus20061_samsung_1440_3216_dsc_cmd_evt {
	qcom,panel_voltage_vddi_name = "vddio";
	qcom,panel_voltage_vddi = <0 1650000 1800000 1950000>;
	qcom,panel_voltage_vddr_name = "vddio";
	qcom,panel_voltage_vddr = <1 1650000 1800000 1950000>;
};

// #ifdef OPLUS_FEATURE_ADFR
// this file is too large, so add OPlus ADFR timing in a overlay dtsi
#include "dsi-panel-oplus20061-samsung-1440-3216-dsc-cmd-evt-overlay.dtsi"
// #endif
